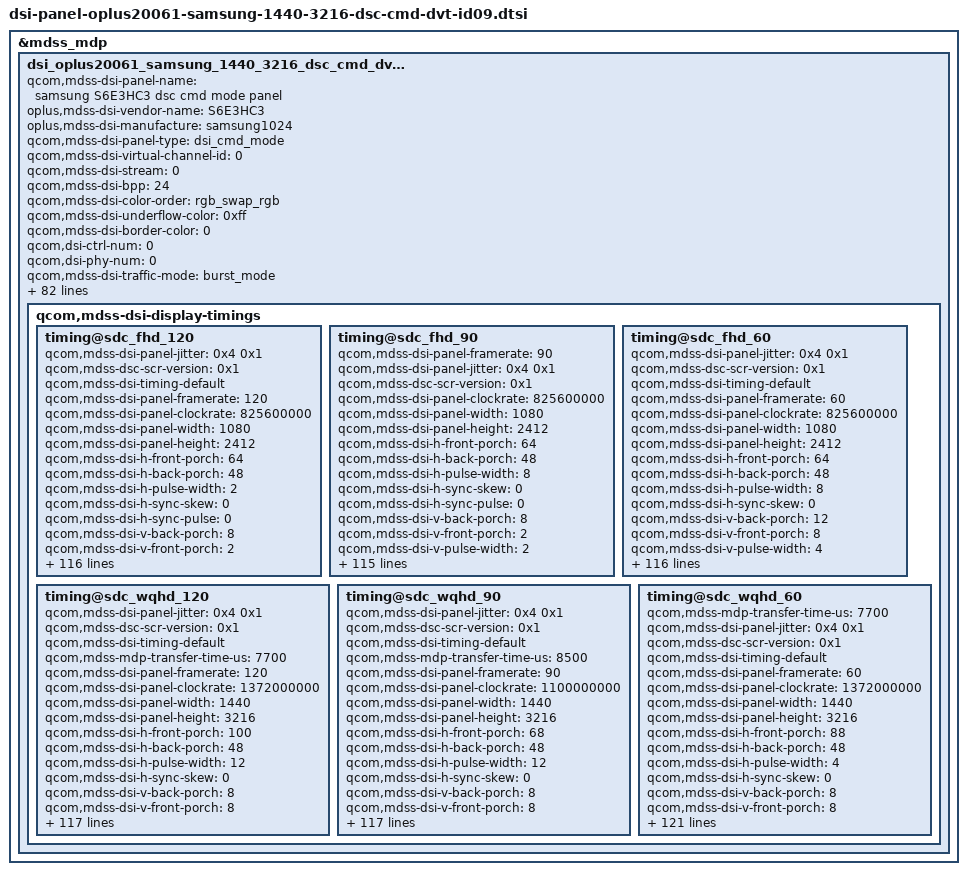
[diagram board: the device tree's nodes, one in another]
&mdss_mdp {
	dsi_oplus20061_samsung_1440_3216_dsc_cmd_dvt_id09: qcom,mdss_dsi_oplus20061_samsung_1440_3216_dsc_cmd_dvt_id09 {
		qcom,mdss-dsi-panel-name = "samsung S6E3HC3 dsc cmd mode panel";
		oplus,mdss-dsi-vendor-name = "S6E3HC3";
		oplus,mdss-dsi-manufacture = "samsung1024";
		qcom,mdss-dsi-panel-type = "dsi_cmd_mode";
		qcom,mdss-dsi-virtual-channel-id = <0>;
		qcom,mdss-dsi-stream = <0>;
		qcom,mdss-dsi-bpp = <24>;
		qcom,mdss-dsi-color-order = "rgb_swap_rgb";
		qcom,mdss-dsi-underflow-color = <0xff>;
		qcom,mdss-dsi-border-color = <0>;
		qcom,dsi-ctrl-num = <0>;
		qcom,dsi-phy-num = <0>;
		qcom,mdss-dsi-traffic-mode = "burst_mode";
		qcom,mdss-dsi-lane-map = "lane_map_0123";
		qcom,mdss-dsi-bllp-eof-power-mode;
		qcom,mdss-dsi-bllp-power-mode;
		qcom,mdss-dsi-lane-0-state;
		qcom,mdss-dsi-lane-1-state;
		qcom,mdss-dsi-lane-2-state;
		qcom,mdss-dsi-lane-3-state;
		qcom,mdss-dsi-dma-trigger = "trigger_sw";
		qcom,mdss-loading-effect;
		qcom,mdss-dsi-mdp-trigger = "none";
		qcom,mdss-dsi-reset-sequence = <1 10>, <0 5>, <1 10>;
		qcom,mdss-dsi-te-pin-select = <1>;
		qcom,mdss-dsi-te-dcs-command = <1>;
		qcom,mdss-pan-physical-width-dimension = <71>;
		qcom,mdss-pan-physical-height-dimension = <157>;
		qcom,mdss-dsi-init-delay-us = <1000>;
		qcom,mdss-dsi-te-check-enable;
		qcom,mdss-dsi-te-using-te-pin;
		qcom,mdss-dsi-lp11-init;
		qcom,mdss-dsi-wr-mem-start = <0x2c>;
		qcom,mdss-dsi-wr-mem-continue = <0x3c>;
		qcom,mdss-dsc-scr-version = <0x1>;
		/* HDR Setting */
		qcom,mdss-dsi-panel-hdr-enabled;
		qcom,mdss-dsi-panel-hdr-color-primaries = <15635 16450 34000 16000 13250 34500 7500 3000>;
		qcom,mdss-dsi-panel-peak-brightness = <5400000>;
		qcom,mdss-dsi-panel-average-brightness = <2000000>;
		qcom,mdss-dsi-panel-blackness-level = <4000>;

		qcom,esd-check-enabled;
		qcom,mdss-dsi-panel-status-check-mode = "reg_read";
		qcom,mdss-dsi-panel-status-command = [
				06 01 00 01 05 00 02 0A 00
			];
		qcom,mdss-dsi-panel-status-command-state = "dsi_hs_mode";
		qcom,mdss-dsi-panel-status-value = <0x9F>;
		qcom,mdss-dsi-panel-status-read-length = <1>;


		qcom,dynamic-mode-switch-enabled;
		qcom,dynamic-mode-switch-type = "dynamic-resolution-switch-immediate";
		qcom,mdss-dsi-display-timings {
			timing@sdc_fhd_120{
				qcom,mdss-dsi-panel-jitter = <0x4 0x1>;
				qcom,mdss-dsc-scr-version = <0x1>;
				qcom,mdss-dsi-timing-default;
				//qcom,mdss-mdp-transfer-time-us = <6000>;
				qcom,mdss-dsi-panel-framerate = <120>;
				qcom,mdss-dsi-panel-clockrate = <825600000>;
				qcom,mdss-dsi-panel-width = <1080>;
				qcom,mdss-dsi-panel-height = <2412>;

				qcom,mdss-dsi-h-front-porch = <64>;
				qcom,mdss-dsi-h-back-porch = <48>;
				qcom,mdss-dsi-h-pulse-width = <2>;
				qcom,mdss-dsi-h-sync-skew = <0>;
				qcom,mdss-dsi-h-sync-pulse = <0>;
				qcom,mdss-dsi-v-back-porch = <8>;
				qcom,mdss-dsi-v-front-porch = <2>;
				qcom,mdss-dsi-v-pulse-width = <2>;
				qcom,mdss-dsi-h-left-border = <0>;
				qcom,mdss-dsi-h-right-border = <0>;
				qcom,mdss-dsi-v-top-border = <0>;
				qcom,mdss-dsi-v-bottom-border = <0>;

				qcom,dsi-select-clocks = "mux_byte_clk0", "mux_pixel_clk0";

				oplus,fod-on-vblank = <0>;
				oplus,fod-off-vblank = <1>;
				qcom,mdss-dsi-panel-read-register-open-command = [
					39 01 00 00 00 00 03 F0 5A 5A
					];
				qcom,mdss-dsi-panel-id1-command = [
					06 01 00 00 00 00 01 E9
					];
				qcom,mdss-dsi-panel-read-register-close-command = [
					39 01 00 00 00 00 03 F0 A5 A5
					];
				qcom,mdss-dsi-timing-switch-command = [
					/* CASET/PASET Setting */
					39 00 00 00 00 00 05 2A 00 00 04 37
					39 00 00 00 00 00 05 2B 00 00 09 6B
					/* Scaler Setting */
					39 00 00 00 00 00 03 F0 5A 5A
					15 00 00 00 00 00 02 C3 89
					39 00 00 00 00 00 04 B0 00 24 C3
					39 00 00 00 00 00 12 C3 FD 00 FD 00 FD 00 FD 00 FD 00 FD 00 FD 00 FD 00 FD
					39 00 00 00 00 00 04 B0 00 3A C3
					39 00 00 00 00 00 12 C3 B0 00 B0 00 B0 00 B0 00 B0 00 B0 00 B0 00 B0 00 B0
					39 00 00 00 00 00 04 B0 00 50 C3
					39 00 00 00 00 00 12 C3 43 00 43 00 43 00 43 00 43 00 43 00 43 00 43 00 43
					39 00 00 00 00 00 04 B0 00 61 C3
					39 00 00 00 00 00 17 C3 CC CC CC CC C0 FE 00 FE 00 FE 00 FE 00 FE 00 FE 00 FE 00 FE 00 FE
					39 00 00 00 00 00 03 F0 A5 A5

					/* OPLUS ADFR OFF */
					39 00 00 00 00 00 03 F0 5A 5A
					39 00 00 00 00 00 03 FC 5A 5A
					15 00 00 00 00 00 02 B9 00						/* TP shift fixed */
					39 00 00 00 00 00 04 B0 00 02 60
					15 00 00 00 00 00 02 60 00						/* OPLUS ADFR OFF */
					39 00 00 00 00 00 03 F2 00 01					/* 0x01,0x00:ADFR ON setting 0x00,0x01:ADFR OFF Setting */
					15 00 00 00 00 00 02 F7 0F
					39 00 00 00 00 00 03 FC A5 A5
					39 00 00 00 00 00 03 F0 A5 A5

					/* TSP_HSYNC(SYNC1) Fixed Setting */
					39 00 00 00 00 00 03 F0 5A 5A
					39 00 00 00 00 00 04 B0 00 22 B9
					39 00 00 00 00 00 03 B9 A1 B1						/* TSP_SYNC1 = TSP_VSYNC ,  TSP_SYNC2 = TSP_HSYNC */
					39 00 00 00 00 00 04 B0 00 3A B9
					15 00 00 00 00 00 02 B9 02						/* TSP_VSYNC Fixed TE 02:120 03:90 05:60 */
					39 00 00 00 00 00 04 B0 00 26 B9
					39 00 00 00 00 00 03 B9 00 00
					15 00 00 00 00 00 02 F7 0F
					39 00 00 00 00 00 03 F0 A5 A5
					/* TSP_SYNC3 Fixed Setting */
					39 00 00 00 00 00 03 F0 5A 5A
					39 00 00 00 00 00 04 B0 00 24 B9
					15 00 00 00 00 00 02 B9 21
					39 00 00 00 00 00 04 B0 00 38 B9
					15 00 00 00 00 00 02 B9 02						/* TSP_VSYNC Fixed TE 02:120 03:90 05:60 */
					39 00 00 00 00 00 04 B0 00 2A B9
					39 00 00 00 00 00 03 B9 00 00
					15 00 00 00 00 00 02 F7 0F
					39 00 00 00 00 00 03 F0 A5 A5

					/* 120hz Transition */
					39 00 00 00 00 00 03 F0 5A 5A
					39 00 00 00 00 00 04 B0 00 16 F2
					39 00 00 00 00 00 03 F2 1B 50					/* 0x1B,0x50:120hz 0x24,0x70:90hz */
					39 00 00 00 00 00 03 BD 21 02					/* 0x21,0x02:120hz 0x21,0x03:90hz */
					15 00 00 00 00 00 02 60 00						/* 0x00:120hz 0x08:90hz 0x01:60hz */
					39 00 00 00 00 00 04 B0 00 10 BD
					15 00 00 00 00 00 02 BD 10						/* 0x00:1frame 0x10:2frame 0x20:3frame */
					15 00 00 00 00 00 02 F7 0F
					39 01 00 00 00 00 03 F0 A5 A5
				];
				qcom,mdss-dsi-on-command = [
					/* DSC Setting */
					39 01 00 00 00 00 5A 9E 11
					00 00 AB 30 80 09 6C 04 38
					00 24 02 1C 02 1C 02 00 02
					3B 00 20 03 35 00 07 00 0E
					03 34 02 D4 18 00 10 F0 07
					10 20 00 06 0F 0F 33 0E 1C
					2A 38 46 54 62 69 70 77 79
					7B 7D 7E 02 02 22 00 2A 40
					2A BE 3A FC 3A FA 3A F8 3B
					38 3B 78 3B B6 4B B6 4B F4
					4B F4 6C 34 84 74 00
					15 01 00 00 00 00 02 9D 01

					/* Sleep Out(11h) */
					05 01 00 00 05 00 01 11

					/* TSP_HSYNC(SYNC1) Fixed Setting */
					39 00 00 00 00 00 03 F0 5A 5A
					39 00 00 00 00 00 04 B0 00 22 B9
					39 00 00 00 00 00 03 B9 A1 B1						/* TSP_SYNC1 = TSP_VSYNC ,  TSP_SYNC2 = TSP_HSYNC */
					39 00 00 00 00 00 04 B0 00 3A B9
					15 00 00 00 00 00 02 B9 02						/* TSP_VSYNC Fixed TE 02:120 03:90 05:60 */
					39 00 00 00 00 00 04 B0 00 26 B9
					39 00 00 00 00 00 03 B9 00 00
					15 00 00 00 00 00 02 F7 0F
					39 01 00 00 00 00 03 F0 A5 A5
					/* TSP_SYNC3 Fixed Setting */
					39 00 00 00 00 00 03 F0 5A 5A
					39 00 00 00 00 00 04 B0 00 24 B9
					15 00 00 00 00 00 02 B9 21
					39 00 00 00 00 00 04 B0 00 38 B9
					15 00 00 00 00 00 02 B9 02						/* TSP_VSYNC Fixed TE 02:120 03:90 05:60 */
					39 00 00 00 00 00 04 B0 00 2A B9
					39 00 00 00 00 00 03 B9 00 00
					15 00 00 00 00 00 02 F7 0F
					39 01 00 00 78 00 03 F0 A5 A5
					/* 120hz Transition */
					39 00 00 00 00 00 03 F0 5A 5A
					39 00 00 00 00 00 04 B0 00 16 F2
					39 00 00 00 00 00 03 F2 1B 50					/* 0x1B,0x50:120hz 0x24,0x70:90hz */
					39 00 00 00 00 00 03 BD 21 02					/* 0x21,0x02:120hz 0x21,0x03:90hz */
					15 00 00 00 00 00 02 60 00						/* 0x00:120hz 0x08:90hz 0x01:60hz */
					39 00 00 00 00 00 04 B0 00 10 BD
					15 00 00 00 00 00 02 BD 10						/* 0x00:1frame 0x10:2frame 0x20:3frame */
					15 00 00 00 00 00 02 F7 0F
					39 01 00 00 00 00 03 F0 A5 A5
					
					/* Common Setting */
					39 00 00 00 00 00 03 F0 5A 5A
					39 00 00 00 00 00 03 F2 00 01					/* FQ_CON Setting */
					39 01 00 00 00 00 03 F0 A5 A5
					/* TE(Vsync) ON */
					39 00 00 00 00 00 03 F0 5A 5A
					15 00 00 00 00 00 02 35 00
					15 00 00 00 00 00 02 B9 00
					39 01 00 00 00 00 03 F0 A5 A5
					/* CASET/PASET Setting */
					39 00 00 00 00 00 05 2A 00 00 04 37
					39 01 00 00 00 00 05 2B 00 00 09 6B
					/* Loading effect compensation Control */
					39 00 00 00 00 00 03 F0 5A 5A
					39 00 00 00 00 00 04 B0 02 B6 1D
					15 00 00 00 00 00 02 1D 05
					39 01 00 00 00 00 03 F0 A5 A5
					/* Scaler Setting */
					39 00 00 00 00 00 03 F0 5A 5A
					15 00 00 00 00 00 02 C3 89
					39 00 00 00 00 00 04 B0 00 24 C3
					39 00 00 00 00 00 12 C3 FD 00 FD 00 FD 00 FD 00 FD 00 FD 00 FD 00 FD 00 FD
					39 00 00 00 00 00 04 B0 00 3A C3
					39 00 00 00 00 00 12 C3 B0 00 B0 00 B0 00 B0 00 B0 00 B0 00 B0 00 B0 00 B0
					39 00 00 00 00 00 04 B0 00 50 C3
					39 00 00 00 00 00 12 C3 43 00 43 00 43 00 43 00 43 00 43 00 43 00 43 00 43
					39 00 00 00 00 00 04 B0 00 61 C3
					39 00 00 00 00 00 17 C3 CC CC CC CC C0 FE 00 FE 00 FE 00 FE 00 FE 00 FE 00 FE 00 FE 00 FE
					39 01 00 00 00 00 03 F0 A5 A5

					/* Brightness Control */
					39 00 00 00 00 00 03 F0 5A 5A
					39 00 00 00 00 00 04 B0 00 0D 63
					15 00 00 00 00 00 02 63 01						/* Dimming Setting */
					39 00 00 00 00 00 04 B0 00 0C 63
					15 00 00 00 00 00 02 63 20
					39 00 00 00 00 00 03 F0 A5 A5
					15 00 00 00 00 00 02 53 20
					//15 01 00 00 00 00 02 F7 0F
					/* Pre-charge setting */
					39 01 00 00 00 00 03 F0 5A 5A
					39 01 00 00 00 00 04 B0 00 2b F6
					39 01 00 00 00 00 04 F6 60 63 69
					39 01 00 00 00 00 02 F7 0F
					39 01 00 00 00 00 03 F0 A5 A5
					/* OPEC ON */
					39 00 00 00 00 00 03 F0 5A 5A
					39 00 00 00 00 00 04 B0 00 56 1F
					39 00 00 00 00 00 11 1F 01 05 01 06 03 24 06 c0 06 c1 0d af 0d b0 1b b0
					39 00 00 00 00 00 04 B0 00 6A 1F
					39 00 00 00 00 00 1D 1F 01 05 03 24 04 4c 05 78 06 c0 08 34 09 c4 0b 54 0d af 0e 10 0e d8 0f a0 10 68 11 30
					39 00 00 00 00 00 04 B0 00 52 1F
					39 00 00 00 00 00 02 1F 02
					39 00 00 00 00 00 04 B0 00 54 1F
					39 00 00 00 00 00 02 1F 00
					39 01 00 00 00 00 03 F0 A5 A5

					/* ACL Mode */
					39 00 00 00 00 00 03 F0 5A 5A
					15 00 00 00 00 00 02 55 00
					39 01 00 00 00 00 03 F0 A5 A5

					/* Display On */
					//05 01 00 00 00 00 01 29
				];
				qcom,mdss-dsi-post-on-backlight = [
					/* Display On */
					05 01 00 00 00 00 01 29
				];
				qcom,mdss-dsi-off-command=[
					05 01 00 00 0A 00 02 28 00
					05 01 00 00 78 00 02 10 00
				];
				qcom,mdss-dsi-lp1-command = [
					05 01 00 00 11 00 01 28
					/* AOD Mode ON Setting */
					39 01 00 00 00 00 03 F0 5A 5A
					15 01 00 00 00 00 02 53 24
					//15 01 00 00 00 00 02 49 01
					39 01 00 00 24 00 03 F0 A5 A5
					05 01 00 00 00 00 01 29
				];
				qcom,mdss-dsi-nolp-command = [
					/* AOD OFF */
					39 01 00 00 00 00 03 F0 5A 5A
					15 01 00 00 00 00 02 53 28
					//15 01 00 00 00 00 02 49 02
					39 01 00 00 00 00 03 F0 A5 A5

					/* ELVSS DIM OFF  */
					39 01 00 00 00 00 03 F0 5A 5A
					39 01 00 00 00 00 04 B0 00 0C 63
					15 01 00 00 00 00 02 63 00
					39 01 00 00 00 00 03 F0 A5 A5
					/* HBM OFF Mode */
					39 01 00 00 00 00 02 53 20
					//39 01 00 00 00 00 03 51 07 FF
				];
				qcom,mdss-dsi-aod-hbm-on-command = [
					/* Loading OFF */
					39 00 00 00 00 00 03 f0 5a 5a
					39 00 00 00 00 00 04 b0 02 b6 1d
					39 00 00 00 00 00 02 1d 05
					39 00 00 00 00 00 03 f0 a5 a5
					/* aor 1.6% */
					39 00 00 00 00 00 03 f0 5a 5a
					39 00 00 00 00 00 04 b0 00 01 bd
					39 00 00 00 00 00 02 bd 02
					39 00 00 00 00 00 04 b0 02 b9 65
					39 00 00 00 00 00 07 65 00 ac 00 ac 00 ac
					39 00 00 00 00 00 02 f7 0f
					39 00 00 00 00 00 03 f0 a5 a5
					/* hbm on */
					15 00 00 00 00 00 02 53 e0
					39 01 00 00 09 00 03 51 0F 1F
				];
				qcom,mdss-dsi-aod-hbm-off-command = [
					/* HBM OFF Mode */
					39 01 00 00 00 00 02 53 20
					//39 01 00 00 00 00 03 51 07 FF
					/* AOD ON */
					39 01 00 00 00 00 03 F0 5A 5A
					15 01 00 00 00 00 02 53 24
					39 01 00 00 00 00 02 49 01
					39 01 00 00 09 00 03 F0 A5 A5
				];
				/*** pvt commond for ID1 >= 05 ***/
				qcom,mdss-dsi-lp1-pvt-command = [
					05 01 00 00 11 00 01 28
					/* AOD Mode ON Setting */
					39 01 00 00 00 00 03 F0 5A 5A
					15 01 00 00 00 00 02 53 24
					39 01 00 00 24 00 03 F0 A5 A5
					05 01 00 00 00 00 01 29
				];
				qcom,mdss-dsi-nolp-pvt-command = [
					/* AOD OFF */
					39 01 00 00 00 00 03 F0 5A 5A
					15 01 00 00 00 00 02 53 28
					39 01 00 00 00 00 03 F0 A5 A5
					/* HBM OFF Mode */
					39 01 00 00 00 00 02 53 20
					//39 01 00 00 00 00 03 51 07 FF
				];
				qcom,mdss-dsi-aod-hbm-on-pvt-command = [
					/* Loading OFF */
					39 00 00 00 00 00 03 f0 5a 5a
					39 00 00 00 00 00 04 b0 02 b6 1d
					39 00 00 00 00 00 02 1d 05
					39 00 00 00 00 00 03 f0 a5 a5
					/* aor 1.6% */
					39 00 00 00 00 00 03 f0 5a 5a
					39 00 00 00 00 00 04 b0 00 01 bd
					39 00 00 00 00 00 02 bd 02
					39 00 00 00 00 00 04 b0 02 b9 65
					39 00 00 00 00 00 07 65 00 ac 00 ac 00 ac
					39 00 00 00 00 00 02 f7 0f
					39 00 00 00 00 00 03 f0 a5 a5
					/* hbm on */
					15 00 00 00 00 00 02 53 e0
					39 01 00 00 09 00 03 51 0F 1F
				];
				qcom,mdss-dsi-aod-hbm-off-pvt-command = [
					/* HBM OFF Mode */
					39 01 00 00 00 00 02 53 20
					//39 01 00 00 00 00 03 51 07 FF
					/* AOD ON */
					39 01 00 00 00 00 03 F0 5A 5A
					15 01 00 00 00 00 02 53 24
					39 01 00 00 09 00 03 F0 A5 A5
				];
				qcom,mdss-dsi-hbm-off-command = [
					/* HBM OFF Mode */
					39 00 00 00 00 00 03 f0 5a 5a
					39 00 00 00 00 00 04 b0 00 0c 63
					15 00 00 00 00 00 02 63 20
					39 00 00 00 00 00 03 f0 a5 a5
					39 01 00 00 09 00 02 53 28
				];
				qcom,mdss-dsi-hbm-on-command = [
					/* DLY ON */
					39 00 00 00 00 00 03 f0 5a 5a
					39 00 00 00 00 00 04 b0 00 0c 63
					39 00 00 00 00 00 02 63 20
					39 01 00 00 09 00 03 f0 a5 a5
					/* Loading OFF */
					39 00 00 00 00 00 03 f0 5a 5a
					39 00 00 00 00 00 04 b0 02 b6 1d
					39 00 00 00 00 00 02 1d 05
					39 00 00 00 00 00 03 f0 a5 a5
					/* aor 1.6% */
					39 00 00 00 00 00 03 f0 5a 5a
					39 00 00 00 00 00 04 b0 00 01 bd
					39 00 00 00 00 00 02 bd 02
					39 00 00 00 00 00 04 b0 02 b9 65
					39 00 00 00 00 00 07 65 00 ac 00 ac 00 ac
					39 00 00 00 00 00 02 f7 0f
					39 00 00 00 00 00 03 f0 a5 a5
					/* hbm on */
					15 01 00 00 09 00 02 53 e0
					39 01 00 00 00 00 03 51 0F 1F
				];
				qcom,mdss-dsi-normal-hbm-on-command = [
					/* Loading OFF */
					39 00 00 00 00 00 03 f0 5a 5a
					39 00 00 00 00 00 04 b0 02 b6 1d
					39 00 00 00 00 00 02 1d 05
					39 00 00 00 00 00 03 f0 a5 a5
					/* aor 1.6% */
					39 00 00 00 00 00 03 f0 5a 5a
					39 00 00 00 00 00 04 b0 00 01 bd
					39 00 00 00 00 00 02 bd 02
					39 00 00 00 00 00 04 b0 02 b9 65
					39 00 00 00 00 00 07 65 00 ac 00 ac 00 ac
					39 00 00 00 00 00 02 f7 0f
					39 00 00 00 00 00 03 f0 a5 a5
					/* hbm on */
					15 01 00 00 09 00 02 53 e0
					39 01 00 00 00 00 03 51 0F 1F
				];
				qcom,mdss-dsi-hbm-enter-switch-command = [
					15 01 00 00 00 00 02 53 E0
				];
				qcom,mdss-dsi-hbm-exit-switch-command = [
					39 01 00 00 00 00 02 53 20
					//39 01 00 00 00 00 03 51 07 FF
				];
				qcom,mdss-dsi-aor-restore-command = [
					/* AOR 16% */
					39 00 00 00 00 00 03 f0 5a 5a
					39 00 00 00 00 00 04 b0 00 01 bd
					39 00 00 00 00 00 02 bd 02
					39 00 00 00 00 00 04 b0 02 b9 65
					39 00 00 00 00 00 07 65 01 5e 01 5e 01 5e
					39 00 00 00 00 00 02 f7 0f
					39 01 00 00 00 00 03 f0 a5 a5
				];
				qcom,mdss-dsi-aod-high-mode-command = [
					/* AOD 50nit */
					39 01 00 00 00 00 03 F0 5A 5A
					15 01 00 00 00 00 02 53 24
					//39 01 00 00 00 00 02 6A 00
					39 01 00 00 00 00 03 F0 A5 A5
				];
				qcom,mdss-dsi-aod-low-mode-command = [
					/* AOD 10nit */
					39 01 00 00 00 00 03 F0 5A 5A
					15 01 00 00 00 00 02 53 27
					//39 01 00 00 00 00 02 6A 00
					39 01 00 00 00 00 03 F0 A5 A5
				];
				qcom,mdss-dsi-seed-off-command = [
					/* SEED CRC OFF*/
					15 01 00 00 00 00 02 1C 00
					/* SEED CRC BYPASS */
					39 01 00 00 00 00 03 F0 5A 5A
					15 01 00 00 00 00 02 1D 01
					39 01 00 00 00 00 03 F0 A5 A5
				];
				qcom,mdss-dsi-seed-0-command = [
					/* SEED CRC Setting*/
					15 01 00 00 00 00 02 1C 05
					39 01 00 00 00 00 03 F0 5A 5A
					39 01 00 00 00 00 04 B0 00 01 1D
					/* SEED DCI-P3 Setting*/
					39 01 00 00 00 00 16 1D FF 00 00 00 FF 00 00 00 FF 00 FF FF FF 00 FF FF FF 00 FF FF FF
					15 01 00 00 00 00 02 1D 00
					39 01 00 00 00 00 03 F0 A5 A5
				];
				qcom,mdss-dsi-seed-1-command = [
					/* SEED CRC Setting*/
					15 01 00 00 00 00 02 1C 05
					39 01 00 00 00 00 03 F0 5A 5A
					39 01 00 00 00 00 04 B0 00 01 1D
					/* SEED DCI-P3 Setting*/
					39 01 00 00 00 00 16 1D FF 00 00 00 FF 00 00 00 FF 00 FF FF FF 00 FF FF FF 00 FF FF FF
					15 01 00 00 00 00 02 1D 00
					39 01 00 00 00 00 03 F0 A5 A5
				];
				qcom,mdss-dsi-seed-2-command = [
					/* SEED CRC Setting*/
					15 01 00 00 00 00 02 1C 05
					39 01 00 00 00 00 03 F0 5A 5A
					39 01 00 00 00 00 04 B0 00 01 1D
					/* SEED DCI-P3 Setting*/
					39 01 00 00 00 00 16 1D FF 00 00 00 FF 00 00 00 FF 00 FF FF FF 00 FF FF FF 00 FF FF FF
					15 01 00 00 00 00 02 1D 00
					39 01 00 00 00 00 03 F0 A5 A5
				];
				qcom,mdss-dsi-loading-effect-1-command = [
					39 00 00 00 00 00 03 F0 5A 5A
					39 00 00 00 00 00 04 B0 02 B6 1D
					39 00 00 00 00 00 02 1D 25
					39 00 00 00 00 00 04 B0 01 A5 1F
					39 00 00 00 00 00 09 1F E2 00 00 00 92 2C 6A 80
					39 00 00 00 00 00 04 B0 01 AD 1F
					39 00 00 00 00 00 07 1F 00 00 00 00 FF 90
					39 00 00 00 00 00 04 B0 01 B5 1F
					39 00 00 00 00 00 04 1F 49 00 10
					39 00 00 00 00 00 04 B0 01 BA 1F
					39 00 00 00 00 00 06 1F 05 FF 10 00 00
					39 00 00 00 00 00 04 B0 01 C1 1F
					39 00 00 00 00 00 05 1F 00 00 00 00
					39 00 00 00 00 00 04 B0 01 C5 1F
					39 00 00 00 00 00 05 1F 03 FF 21 3C
					39 01 00 00 00 00 03 F0 A5 A5
				];
				qcom,mdss-dsi-loading-effect-2-command = [
					39 00 00 00 00 00 03 F0 5A 5A
					39 00 00 00 00 00 04 B0 02 B6 1D
					39 00 00 00 00 00 02 1D 25
					39 00 00 00 00 00 04 B0 01 A5 1F
					39 00 00 00 00 00 09 1F E2 00 00 00 92 2C 6A 80
					39 00 00 00 00 00 04 B0 01 AD 1F
					39 00 00 00 00 00 07 1F 7D 64 7E 65 FF 90
					39 00 00 00 00 00 04 B0 01 B5 1F
					39 00 00 00 00 00 04 1F 49 00 10
					39 00 00 00 00 00 04 B0 01 BA 1F
					39 00 00 00 00 00 06 1F 05 FF 10 00 00
					39 00 00 00 00 00 04 B0 01 C1 1F
					39 00 00 00 00 00 05 1F 00 00 00 00
					39 00 00 00 00 00 04 B0 01 C5 1F
					39 00 00 00 00 00 05 1F 03 FF 21 3C
					39 01 00 00 00 00 03 F0 A5 A5
				];
				qcom,mdss-dsi-loading-effect-off-command = [
					39 00 00 00 00 00 03 F0 5A 5A
					39 00 00 00 00 00 04 B0 02 B6 1D
					39 00 00 00 00 00 02 1D 05
					39 01 00 00 00 00 03 F0 A5 A5
				];
				qcom,mdss-dsi-aod-hbm-on-command-state = "dsi_hs_mode";
				qcom,mdss-dsi-aod-hbm-off-command-state = "dsi_hs_mode";
				qcom,mdss-dsi-timing-switch-command-state = "dsi_hs_mode";
				qcom,mdss-dsi-on-command-state = "dsi_lp_mode";
				qcom,mdss-dsi-off-command-state = "dsi_hs_mode";
				qcom,mdss-dsi-seed-off-command-state = "dsi_hs_mode";
				qcom,mdss-dsi-seed-0-command-state = "dsi_hs_mode";
				qcom,mdss-dsi-seed-1-command-state = "dsi_hs_mode";
				qcom,mdss-dsi-seed-2-command-state = "dsi_hs_mode";
				qcom,mdss-dsi-loading-effect-1-command-state = "dsi_hs_mode";
				qcom,mdss-dsi-loading-effect-2-command-state = "dsi_hs_mode";
				qcom,mdss-dsi-loading-effect-off-command-state = "dsi_hs_mode";
				qcom,mdss-dsi-hbm-on-command-state = "dsi_hs_mode";
				qcom,mdss-dsi-hbm-off-command-state = "dsi_hs_mode";
				qcom,mdss-dsi-aor-restore-command-state = "dsi_hs_mode";

				qcom,compression-mode = "dsc";
				qcom,lm-split = <540 540>;
				qcom,mdss-dsc-encoders = <2>;
				qcom,mdss-dsc-slice-height = <36>;
				qcom,mdss-dsc-slice-width = <540>;
				qcom,mdss-dsc-slice-per-pkt = <2>;
				qcom,mdss-dsc-bit-per-component = <10>;
				qcom,mdss-dsc-bit-per-pixel = <8>;
				qcom,mdss-dsc-block-prediction-enable;
				qcom,mdss-dsi-panel-id1-command-state = "dsi_lp_mode";
				qcom,mdss-dsi-panel-read-register-open-state = "dsi_lp_mode";
				qcom,mdss-dsi-panel-read-register-close-state = "dsi_lp_mode";
			};
			timing@sdc_fhd_90{
				//qcom,mdss-dsi-timing-default;
				//qcom,mdss-mdp-transfer-time-us = <7700>;
				qcom,mdss-dsi-panel-framerate = <90>;
				qcom,mdss-dsi-panel-jitter = <0x4 0x1>;
				qcom,mdss-dsc-scr-version = <0x1>;
				qcom,mdss-dsi-panel-clockrate = <825600000>;
				qcom,mdss-dsi-panel-width = <1080>;
				qcom,mdss-dsi-panel-height = <2412>;

				qcom,mdss-dsi-h-front-porch = <64>;
				qcom,mdss-dsi-h-back-porch = <48>;
				qcom,mdss-dsi-h-pulse-width = <8>;
				qcom,mdss-dsi-h-sync-skew = <0>;
				qcom,mdss-dsi-h-sync-pulse = <0>;
				qcom,mdss-dsi-v-back-porch = <8>;
				qcom,mdss-dsi-v-front-porch = <2>;
				qcom,mdss-dsi-v-pulse-width = <2>;
				qcom,mdss-dsi-h-left-border = <0>;
				qcom,mdss-dsi-h-right-border = <0>;
				qcom,mdss-dsi-v-top-border = <0>;
				qcom,mdss-dsi-v-bottom-border = <0>;

				qcom,dsi-select-clocks = "mux_byte_clk0", "mux_pixel_clk0";

				oplus,fod-on-vblank = <0>;
				oplus,fod-off-vblank = <1>;
				qcom,mdss-dsi-panel-read-register-open-command = [
					39 01 00 00 00 00 03 F0 5A 5A
					];
				qcom,mdss-dsi-panel-id1-command = [
					06 01 00 00 00 00 01 E9
					];
				qcom,mdss-dsi-panel-read-register-close-command = [
					39 01 00 00 00 00 03 F0 A5 A5
					];
				qcom,mdss-dsi-timing-switch-command = [
					/* CASET/PASET Setting */
					39 00 00 00 00 00 05 2A 00 00 04 37
					39 00 00 00 00 00 05 2B 00 00 09 6B
					/* Scaler Setting */
					39 00 00 00 00 00 03 F0 5A 5A
					15 00 00 00 00 00 02 C3 89
					39 00 00 00 00 00 04 B0 00 24 C3
					39 00 00 00 00 00 12 C3 FD 00 FD 00 FD 00 FD 00 FD 00 FD 00 FD 00 FD 00 FD
					39 00 00 00 00 00 04 B0 00 3A C3
					39 00 00 00 00 00 12 C3 B0 00 B0 00 B0 00 B0 00 B0 00 B0 00 B0 00 B0 00 B0
					39 00 00 00 00 00 04 B0 00 50 C3
					39 00 00 00 00 00 12 C3 43 00 43 00 43 00 43 00 43 00 43 00 43 00 43 00 43
					39 00 00 00 00 00 04 B0 00 61 C3
					39 00 00 00 00 00 17 C3 CC CC CC CC C0 FE 00 FE 00 FE 00 FE 00 FE 00 FE 00 FE 00 FE 00 FE
					39 00 00 00 00 00 03 F0 A5 A5

					/* OPLUS ADFR OFF */
					39 00 00 00 00 00 03 F0 5A 5A
					39 00 00 00 00 00 03 FC 5A 5A
					15 00 00 00 00 00 02 B9 00						/* TP shift fixed */
					39 00 00 00 00 00 04 B0 00 02 60
					15 00 00 00 00 00 02 60 00						/* OPLUS ADFR OFF */
					39 00 00 00 00 00 03 F2 00 01					/* 0x01,0x00:ADFR ON setting 0x00,0x01:ADFR OFF Setting */
					15 00 00 00 00 00 02 F7 0F
					39 00 00 00 00 00 03 FC A5 A5
					39 00 00 00 00 00 03 F0 A5 A5

					/* TSP_HSYNC(SYNC1) Fixed Setting */
					39 00 00 00 00 00 03 F0 5A 5A
					39 00 00 00 00 00 04 B0 00 22 B9
					39 00 00 00 00 00 03 B9 A1 B1						/* TSP_SYNC1 = TSP_VSYNC ,  TSP_SYNC2 = TSP_HSYNC */
					39 00 00 00 00 00 04 B0 00 3A B9
					15 00 00 00 00 00 02 B9 03						/* TSP_VSYNC Fixed TE 02:120 03:90 05:60 */
					39 00 00 00 00 00 04 B0 00 26 B9
					39 00 00 00 00 00 03 B9 00 00
					15 00 00 00 00 00 02 F7 0F
					39 00 00 00 00 00 03 F0 A5 A5
					/* TSP_SYNC3 Fixed Setting */
					39 00 00 00 00 00 03 F0 5A 5A
					39 00 00 00 00 00 04 B0 00 24 B9
					15 00 00 00 00 00 02 B9 21
					39 00 00 00 00 00 04 B0 00 38 B9
					15 00 00 00 00 00 02 B9 03						/* TSP_VSYNC Fixed TE 02:120 03:90 05:60 */
					39 00 00 00 00 00 04 B0 00 2A B9
					39 00 00 00 00 00 03 B9 00 00
					15 00 00 00 00 00 02 F7 0F
					39 00 00 00 00 00 03 F0 A5 A5

					/* 90hz Transition */
					39 00 00 00 00 00 03 F0 5A 5A
					39 00 00 00 00 00 04 B0 00 16 F2
					39 00 00 00 00 00 03 F2 24 70					/* 0x1B,0x50:120hz 0x24,0x70:90hz */
					39 00 00 00 00 00 03 BD 21 03					/* 0x21,0x02:120hz 0x21,0x03:90hz */
					15 00 00 00 00 00 02 60 08						/* 0x00:120hz 0x08:90hz 0x01:60hz */
					39 00 00 00 00 00 04 B0 00 10 BD
					15 00 00 00 00 00 02 BD 10						/* 0x00:1frame 0x10:2frame 0x20:3frame */
					15 00 00 00 00 00 02 F7 0F
					39 01 00 00 00 00 03 F0 A5 A5
				];
				qcom,mdss-dsi-on-command = [
					/* DSC Setting */
					39 01 00 00 00 00 5A 9E 11
					00 00 AB 30 80 09 6C 04 38
					00 24 02 1C 02 1C 02 00 02
					3B 00 20 03 35 00 07 00 0E
					03 34 02 D4 18 00 10 F0 07
					10 20 00 06 0F 0F 33 0E 1C
					2A 38 46 54 62 69 70 77 79
					7B 7D 7E 02 02 22 00 2A 40
					2A BE 3A FC 3A FA 3A F8 3B
					38 3B 78 3B B6 4B B6 4B F4
					4B F4 6C 34 84 74 00
					15 01 00 00 00 00 02 9D 01

					/* Sleep Out(11h) */
					05 01 00 00 05 00 01 11

					/* TSP_HSYNC(SYNC1) Fixed Setting */
					39 00 00 00 00 00 03 F0 5A 5A
					39 00 00 00 00 00 04 B0 00 22 B9
					39 00 00 00 00 00 03 B9 A1 B1						/* TSP_SYNC1 = TSP_VSYNC ,  TSP_SYNC2 = TSP_HSYNC */
					39 00 00 00 00 00 04 B0 00 3A B9
					15 00 00 00 00 00 02 B9 03						/* TSP_VSYNC Fixed TE 02:120 03:90 05:60 */
					39 00 00 00 00 00 04 B0 00 26 B9
					39 00 00 00 00 00 03 B9 00 00
					15 00 00 00 00 00 02 F7 0F
					39 00 00 00 00 00 03 F0 A5 A5
					/* TSP_SYNC3 Fixed Setting */
					39 00 00 00 00 00 03 F0 5A 5A
					39 00 00 00 00 00 04 B0 00 24 B9
					15 00 00 00 00 00 02 B9 21
					39 00 00 00 00 00 04 B0 00 38 B9
					15 00 00 00 00 00 02 B9 03						/* TSP_VSYNC Fixed TE 02:120 03:90 05:60 */
					39 00 00 00 00 00 04 B0 00 2A B9
					39 00 00 00 00 00 03 B9 00 00
					15 00 00 00 00 00 02 F7 0F
					39 01 00 00 78 00 03 F0 A5 A5
					/* 90hz Transition */
					39 00 00 00 00 00 03 F0 5A 5A
					39 00 00 00 00 00 04 B0 00 16 F2
					39 00 00 00 00 00 03 F2 24 70					/* 0x1B,0x50:120hz 0x24,0x70:90hz */
					39 00 00 00 00 00 03 BD 21 03					/* 0x21,0x02:120hz 0x21,0x03:90hz */
					15 00 00 00 00 00 02 60 08						/* 0x00:120hz 0x08:90hz 0x01:60hz */
					39 00 00 00 00 00 04 B0 00 10 BD
					15 00 00 00 00 00 02 BD 10						/* 0x00:1frame 0x10:2frame 0x20:3frame */
					15 00 00 00 00 00 02 F7 0F
					39 01 00 00 00 00 03 F0 A5 A5
					
					/* Common Setting */
					39 00 00 00 00 00 03 F0 5A 5A
					39 00 00 00 00 00 03 F2 00 01					/* FQ_CON Setting */
					39 01 00 00 00 00 03 F0 A5 A5
					/* TE(Vsync) ON */
					39 00 00 00 00 00 03 F0 5A 5A
					15 00 00 00 00 00 02 35 00
					15 00 00 00 00 00 02 B9 00
					39 01 00 00 00 00 03 F0 A5 A5
					/* CASET/PASET Setting */
					39 00 00 00 00 00 05 2A 00 00 04 37
					39 01 00 00 00 00 05 2B 00 00 09 6B
					/* Loading effect compensation Control */
					39 00 00 00 00 00 03 F0 5A 5A
					39 00 00 00 00 00 04 B0 02 B6 1D
					15 00 00 00 00 00 02 1D 05
					39 01 00 00 00 00 03 F0 A5 A5
					/* Scaler Setting */
					39 00 00 00 00 00 03 F0 5A 5A
					15 00 00 00 00 00 02 C3 89
					39 00 00 00 00 00 04 B0 00 24 C3
					39 00 00 00 00 00 12 C3 FD 00 FD 00 FD 00 FD 00 FD 00 FD 00 FD 00 FD 00 FD
					39 00 00 00 00 00 04 B0 00 3A C3
					39 00 00 00 00 00 12 C3 B0 00 B0 00 B0 00 B0 00 B0 00 B0 00 B0 00 B0 00 B0
					39 00 00 00 00 00 04 B0 00 50 C3
					39 00 00 00 00 00 12 C3 43 00 43 00 43 00 43 00 43 00 43 00 43 00 43 00 43
					39 00 00 00 00 00 04 B0 00 61 C3
					39 00 00 00 00 00 17 C3 CC CC CC CC C0 FE 00 FE 00 FE 00 FE 00 FE 00 FE 00 FE 00 FE 00 FE
					39 01 00 00 00 00 03 F0 A5 A5

					/* Brightness Control */
					39 00 00 00 00 00 03 F0 5A 5A
					39 00 00 00 00 00 04 B0 00 0D 63
					15 00 00 00 00 00 02 63 01						/* Dimming Setting */
					39 00 00 00 00 00 04 B0 00 0C 63
					15 00 00 00 00 00 02 63 20
					39 01 00 00 00 00 03 F0 A5 A5
					15 01 00 00 00 00 02 53 20
					//15 01 00 00 00 00 02 F7 0F
					/* Pre-charge setting */
					39 01 00 00 00 00 03 F0 5A 5A
					39 01 00 00 00 00 04 B0 00 2b F6
					39 01 00 00 00 00 04 F6 60 63 69
					39 01 00 00 00 00 02 F7 0F
					39 01 00 00 00 00 03 F0 A5 A5
					/* OPEC ON */
					39 00 00 00 00 00 03 F0 5A 5A
					39 00 00 00 00 00 04 B0 00 56 1F
					39 00 00 00 00 00 11 1F 01 05 01 06 03 24 06 c0 06 c1 0d af 0d b0 1b b0
					39 00 00 00 00 00 04 B0 00 6A 1F
					39 00 00 00 00 00 1D 1F 01 05 03 24 04 4c 05 78 06 c0 08 34 09 c4 0b 54 0d af 0e 10 0e d8 0f a0 10 68 11 30
					39 00 00 00 00 00 04 B0 00 52 1F
					39 00 00 00 00 00 02 1F 02
					39 00 00 00 00 00 04 B0 00 54 1F
					39 00 00 00 00 00 02 1F 00
					39 01 00 00 00 00 03 F0 A5 A5

					/* ACL Mode */
					39 00 00 00 00 00 03 F0 5A 5A
					15 00 00 00 00 00 02 55 00
					39 01 00 00 00 00 03 F0 A5 A5

					/* Display On */
					//05 01 00 00 00 00 01 29
				];
				qcom,mdss-dsi-post-on-backlight = [
					/* Display On */
					05 01 00 00 00 00 01 29
				];
				qcom,mdss-dsi-off-command=[
					05 01 00 00 0A 00 02 28 00
					05 01 00 00 78 00 02 10 00
				];
				qcom,mdss-dsi-lp1-command = [
					05 01 00 00 11 00 01 28
					/* AOD Mode ON Setting */
					39 01 00 00 00 00 03 F0 5A 5A
					15 01 00 00 00 00 02 53 24
					//15 01 00 00 00 00 02 49 01
					39 01 00 00 24 00 03 F0 A5 A5
					05 01 00 00 00 00 01 29
				];
				qcom,mdss-dsi-nolp-command = [
					/* AOD OFF */
					39 00 00 00 00 00 03 F0 5A 5A
					15 00 00 00 00 00 02 53 28
					39 01 00 00 00 00 03 F0 A5 A5

					/* AOR 16% */
					39 00 00 00 00 00 03 f0 5a 5a
					39 00 00 00 00 00 04 b0 00 01 bd
					39 00 00 00 00 00 02 bd 02
					39 00 00 00 00 00 04 b0 02 d9 65
					39 00 00 00 00 00 07 65 01 06 01 06 01 06
					39 00 00 00 00 00 02 f7 0f
					39 01 00 00 00 00 03 f0 a5 a5
					/* HBM OFF Mode */
					39 01 00 00 00 00 02 53 20
					//39 01 00 00 00 00 03 51 07 FF
				];
				qcom,mdss-dsi-aod-hbm-on-command = [
					/* Loading OFF */
					39 00 00 00 00 00 03 F0 5A 5A
					39 00 00 00 00 00 04 B0 02 B6 1D
					39 00 00 00 00 00 02 1D 05
					39 01 00 00 00 00 03 F0 A5 A5
					/* AOD OFF */
					39 00 00 00 00 00 03 F0 5A 5A
					39 00 00 00 00 00 02 53 28
					39 01 00 00 00 00 03 F0 A5 A5
					/* AOR 1.6% */
					39 00 00 00 00 00 03 F0 5A 5A
					39 00 00 00 00 00 04 B0 00 01 BD
					39 00 00 00 00 00 02 BD 00
					39 00 00 00 00 00 04 B0 02 d9 65
					39 00 00 00 00 00 07 65 00 AC 00 AC 00 AC
					39 00 00 00 00 00 02 F7 0F
					39 01 00 00 00 00 03 F0 A5 A5
					/* Hbm ON */
					15 01 00 00 00 00 02 53 E0
					39 01 00 00 00 00 03 51 0F 1F
				];
				qcom,mdss-dsi-aod-hbm-off-command = [
					/* HBM OFF Mode */
					39 01 00 00 00 00 02 53 20
					//39 01 00 00 00 00 03 51 07 FF
					/* AOD ON */
					39 01 00 00 00 00 03 F0 5A 5A
					15 01 00 00 00 00 02 53 24
					39 01 00 00 00 00 02 49 01
					39 01 00 00 00 00 03 F0 A5 A5
				];
				/*** pvt commond for ID1 >= 05 ***/
				qcom,mdss-dsi-lp1-pvt-command = [
					05 01 00 00 11 00 01 28
					/* AOD Mode ON Setting */
					39 01 00 00 00 00 03 F0 5A 5A
					15 01 00 00 00 00 02 53 24
					39 01 00 00 24 00 03 F0 A5 A5
					05 01 00 00 00 00 01 29
				];
				qcom,mdss-dsi-nolp-pvt-command = [
					/* AOD OFF */
					39 01 00 00 00 00 03 F0 5A 5A
					15 01 00 00 00 00 02 53 28
					39 01 00 00 00 00 03 F0 A5 A5
					/* HBM OFF Mode */
					39 01 00 00 00 00 02 53 20
					//39 01 00 00 00 00 03 51 07 FF
				];
				qcom,mdss-dsi-aod-hbm-on-pvt-command = [
					/* Loading OFF */
					39 00 00 00 00 00 03 F0 5A 5A
					39 00 00 00 00 00 04 B0 02 B6 1D
					39 00 00 00 00 00 02 1D 05
					39 01 00 00 00 00 03 F0 A5 A5
					/* AOD OFF */
					39 00 00 00 00 00 03 F0 5A 5A
					39 00 00 00 00 00 02 53 28
					39 01 00 00 00 00 03 F0 A5 A5
					/* AOR 1.6% */
					39 00 00 00 00 00 03 F0 5A 5A
					39 00 00 00 00 00 04 B0 00 01 BD
					39 00 00 00 00 00 02 BD 00
					39 00 00 00 00 00 04 B0 02 D9 65
					39 00 00 00 00 00 07 65 00 AC 00 AC 00 AC
					39 00 00 00 00 00 02 F7 0F
					39 01 00 00 00 00 03 F0 A5 A5
					/* Hbm ON */
					15 01 00 00 00 00 02 53 E0
					39 01 00 00 00 00 03 51 0F 1F
				];
				qcom,mdss-dsi-aod-hbm-off-pvt-command = [
					/* HBM OFF Mode */
					39 01 00 00 00 00 02 53 20
					//39 01 00 00 00 00 03 51 07 FF
					/* AOD ON */
					39 01 00 00 00 00 03 F0 5A 5A
					15 01 00 00 00 00 02 53 24
					39 01 00 00 00 00 03 F0 A5 A5
				];
				qcom,mdss-dsi-hbm-off-command = [
					/* HBM OFF Mode */
					39 01 00 00 00 00 02 53 28
					//39 01 00 00 00 00 03 51 07 FF
				];
				qcom,mdss-dsi-hbm-on-command = [
					/* DLY ON */
					39 00 00 00 00 00 03 f0 5a 5a
					39 00 00 00 00 00 04 b0 00 0c 63
					39 00 00 00 00 00 02 63 20
					39 01 00 00 09 00 03 f0 a5 a5
					/* Loading OFF */
					39 00 00 00 00 00 03 F0 5A 5A
					39 00 00 00 00 00 04 B0 02 B6 1D
					39 00 00 00 00 00 02 1D 05
					39 01 00 00 00 00 03 F0 A5 A5
					/* AOR 1.6% */
					39 00 00 00 00 00 03 F0 5A 5A
					39 00 00 00 00 00 04 B0 00 01 BD
					39 00 00 00 00 00 02 BD 00
					39 00 00 00 00 00 04 B0 02 d9 65
					39 00 00 00 00 00 07 65 00 AC 00 AC 00 AC
					39 00 00 00 00 00 02 F7 0F
					39 01 00 00 00 00 03 F0 A5 A5
					/* Hbm ON */
					15 01 00 00 00 00 02 53 E0
					39 01 00 00 00 00 03 51 0F 1F
				];
				qcom,mdss-dsi-normal-hbm-on-command = [
					/* Loading OFF */
					39 00 00 00 00 00 03 F0 5A 5A
					39 00 00 00 00 00 04 B0 02 B6 1D
					39 00 00 00 00 00 02 1D 05
					39 01 00 00 00 00 03 F0 A5 A5
					/* AOR 1.6% */
					39 00 00 00 00 00 03 F0 5A 5A
					39 00 00 00 00 00 04 B0 00 01 BD
					39 00 00 00 00 00 02 BD 00
					39 00 00 00 00 00 04 B0 02 d9 65
					39 00 00 00 00 00 07 65 00 AC 00 AC 00 AC
					39 00 00 00 00 00 02 F7 0F
					39 01 00 00 00 00 03 F0 A5 A5
					/* Hbm ON */
					15 01 00 00 00 00 02 53 E0
					39 01 00 00 00 00 03 51 0F 1F
				];
				qcom,mdss-dsi-hbm-enter-switch-command = [
					15 01 00 00 00 00 02 53 E0
				];
				qcom,mdss-dsi-hbm-exit-switch-command = [
					39 01 00 00 00 00 02 53 20
					//39 01 00 00 00 00 03 51 07 FF
				];
				qcom,mdss-dsi-aor-restore-command = [
					/* AOR 16% */
					39 00 00 00 00 00 03 f0 5a 5a
					39 00 00 00 00 00 04 b0 00 01 bd
					39 00 00 00 00 00 02 bd 03
					39 00 00 00 00 00 04 b0 02 d9 65
					39 00 00 00 00 00 07 65 01 06 01 06 01 06
					39 00 00 00 00 00 02 f7 0f
					39 01 00 00 00 00 03 f0 a5 a5
				];
				qcom,mdss-dsi-aod-high-mode-command = [
					/* AOD 50nit */
					39 01 00 00 00 00 03 F0 5A 5A
					15 01 00 00 00 00 02 53 24
					//39 01 00 00 00 00 02 6A 00
					39 01 00 00 00 00 03 F0 A5 A5
				];
				qcom,mdss-dsi-aod-low-mode-command = [
					/* AOD 10nit */
					39 01 00 00 00 00 03 F0 5A 5A
					15 01 00 00 00 00 02 53 27
					//39 01 00 00 00 00 02 6A 00
					39 01 00 00 00 00 03 F0 A5 A5
				];
				qcom,mdss-dsi-seed-off-command = [
					/* SEED CRC OFF*/
					15 01 00 00 00 00 02 1C 00
					/* SEED CRC BYPASS */
					39 01 00 00 00 00 03 F0 5A 5A
					15 01 00 00 00 00 02 1D 01
					39 01 00 00 00 00 03 F0 A5 A5
				];
				qcom,mdss-dsi-seed-0-command = [
					/* SEED CRC Setting*/
					15 01 00 00 00 00 02 1C 05
					39 01 00 00 00 00 03 F0 5A 5A
					39 01 00 00 00 00 04 B0 00 01 1D
					/* SEED DCI-P3 Setting*/
					39 01 00 00 00 00 16 1D FF 00 00 00 FF 00 00 00 FF 00 FF FF FF 00 FF FF FF 00 FF FF FF
					15 01 00 00 00 00 02 1D 00
					39 01 00 00 00 00 03 F0 A5 A5
				];
				qcom,mdss-dsi-seed-1-command = [
					/* SEED CRC Setting*/
					15 01 00 00 00 00 02 1C 05
					39 01 00 00 00 00 03 F0 5A 5A
					39 01 00 00 00 00 04 B0 00 01 1D
					/* SEED DCI-P3 Setting*/
					39 01 00 00 00 00 16 1D FF 00 00 00 FF 00 00 00 FF 00 FF FF FF 00 FF FF FF 00 FF FF FF
					15 01 00 00 00 00 02 1D 00
					39 01 00 00 00 00 03 F0 A5 A5
				];
				qcom,mdss-dsi-seed-2-command = [
					/* SEED CRC Setting*/
					15 01 00 00 00 00 02 1C 05
					39 01 00 00 00 00 03 F0 5A 5A
					39 01 00 00 00 00 04 B0 00 01 1D
					/* SEED DCI-P3 Setting*/
					39 01 00 00 00 00 16 1D FF 00 00 00 FF 00 00 00 FF 00 FF FF FF 00 FF FF FF 00 FF FF FF
					15 01 00 00 00 00 02 1D 00
					39 01 00 00 00 00 03 F0 A5 A5
				];
				qcom,mdss-dsi-loading-effect-1-command = [
					39 00 00 00 00 00 03 F0 5A 5A
					39 00 00 00 00 00 04 B0 02 B6 1D
					39 00 00 00 00 00 02 1D 25
					39 00 00 00 00 00 04 B0 01 A5 1F
					39 00 00 00 00 00 09 1F E2 00 00 00 92 2C 6A 80
					39 00 00 00 00 00 04 B0 01 AD 1F
					39 00 00 00 00 00 07 1F 00 00 00 00 FF 90
					39 00 00 00 00 00 04 B0 01 B5 1F
					39 00 00 00 00 00 04 1F 49 00 10
					39 00 00 00 00 00 04 B0 01 BA 1F
					39 00 00 00 00 00 06 1F 05 FF 10 00 00
					39 00 00 00 00 00 04 B0 01 C1 1F
					39 00 00 00 00 00 05 1F 00 00 00 00
					39 00 00 00 00 00 04 B0 01 C5 1F
					39 00 00 00 00 00 05 1F 03 FF 21 3C
					39 01 00 00 00 00 03 F0 A5 A5
				];
				qcom,mdss-dsi-loading-effect-2-command = [
					39 00 00 00 00 00 03 F0 5A 5A
					39 00 00 00 00 00 04 B0 02 B6 1D
					39 00 00 00 00 00 02 1D 25
					39 00 00 00 00 00 04 B0 01 A5 1F
					39 00 00 00 00 00 09 1F E2 00 00 00 92 2C 6A 80
					39 00 00 00 00 00 04 B0 01 AD 1F
					39 00 00 00 00 00 07 1F 7D 64 7E 65 FF 90
					39 00 00 00 00 00 04 B0 01 B5 1F
					39 00 00 00 00 00 04 1F 49 00 10
					39 00 00 00 00 00 04 B0 01 BA 1F
					39 00 00 00 00 00 06 1F 05 FF 10 00 00
					39 00 00 00 00 00 04 B0 01 C1 1F
					39 00 00 00 00 00 05 1F 00 00 00 00
					39 00 00 00 00 00 04 B0 01 C5 1F
					39 00 00 00 00 00 05 1F 03 FF 21 3C
					39 01 00 00 00 00 03 F0 A5 A5
				];
				qcom,mdss-dsi-loading-effect-off-command = [
					39 00 00 00 00 00 03 F0 5A 5A
					39 00 00 00 00 00 04 B0 02 B6 1D
					39 00 00 00 00 00 02 1D 05
					39 01 00 00 00 00 03 F0 A5 A5
				];
				qcom,mdss-dsi-aod-hbm-on-command-state = "dsi_hs_mode";
				qcom,mdss-dsi-aod-hbm-off-command-state = "dsi_hs_mode";
				qcom,mdss-dsi-timing-switch-command-state = "dsi_hs_mode";
				qcom,mdss-dsi-on-command-state = "dsi_lp_mode";
				qcom,mdss-dsi-off-command-state = "dsi_hs_mode";
				qcom,mdss-dsi-seed-off-command-state = "dsi_hs_mode";
				qcom,mdss-dsi-seed-0-command-state = "dsi_hs_mode";
				qcom,mdss-dsi-seed-1-command-state = "dsi_hs_mode";
				qcom,mdss-dsi-seed-2-command-state = "dsi_hs_mode";
				qcom,mdss-dsi-loading-effect-1-command-state = "dsi_hs_mode";
				qcom,mdss-dsi-loading-effect-2-command-state = "dsi_hs_mode";
				qcom,mdss-dsi-loading-effect-off-command-state = "dsi_hs_mode";
				qcom,mdss-dsi-hbm-on-command-state = "dsi_hs_mode";
				qcom,mdss-dsi-hbm-off-command-state = "dsi_hs_mode";
				qcom,mdss-dsi-aor-restore-command-state = "dsi_hs_mode";

				qcom,compression-mode = "dsc";
				qcom,lm-split = <540 540>;
				qcom,mdss-dsc-encoders = <2>;
				qcom,mdss-dsc-slice-height = <36>;
				qcom,mdss-dsc-slice-width = <540>;
				qcom,mdss-dsc-slice-per-pkt = <2>;
				qcom,mdss-dsc-bit-per-component = <10>;
				qcom,mdss-dsc-bit-per-pixel = <8>;
				qcom,mdss-dsc-block-prediction-enable;
				qcom,mdss-dsi-panel-id1-command-state = "dsi_lp_mode";
				qcom,mdss-dsi-panel-read-register-open-state = "dsi_lp_mode";
				qcom,mdss-dsi-panel-read-register-close-state = "dsi_lp_mode";
			};
			timing@sdc_fhd_60{
				//qcom,mdss-mdp-transfer-time-us = <7700>;
				qcom,mdss-dsi-panel-jitter = <0x4 0x1>;
				qcom,mdss-dsc-scr-version = <0x1>;
				qcom,mdss-dsi-timing-default;
				qcom,mdss-dsi-panel-framerate = <60>;
				qcom,mdss-dsi-panel-clockrate = <825600000>;
				qcom,mdss-dsi-panel-width = <1080>;
				qcom,mdss-dsi-panel-height = <2412>;

				qcom,mdss-dsi-h-front-porch = <64>;
				qcom,mdss-dsi-h-back-porch = <48>;
				qcom,mdss-dsi-h-pulse-width = <8>;
				qcom,mdss-dsi-h-sync-skew = <0>;
				qcom,mdss-dsi-v-back-porch = <12>;
				qcom,mdss-dsi-v-front-porch = <8>;
				qcom,mdss-dsi-v-pulse-width = <4>;
				qcom,mdss-dsi-h-sync-pulse = <0>;

				qcom,mdss-dsi-h-left-border = <0>;
				qcom,mdss-dsi-h-right-border = <0>;
				qcom,mdss-dsi-v-top-border = <0>;
				qcom,mdss-dsi-v-bottom-border = <0>;

				qcom,dsi-select-clocks = "mux_byte_clk0", "mux_pixel_clk0";

				oplus,fod-on-vblank = <0>;
				oplus,fod-off-vblank = <0>;
				qcom,mdss-dsi-panel-read-register-open-command = [
					39 01 00 00 00 00 03 F0 5A 5A
					];
				qcom,mdss-dsi-panel-id1-command = [
					06 01 00 00 00 00 01 E9
					];
				qcom,mdss-dsi-panel-read-register-close-command = [
					39 01 00 00 00 00 03 F0 A5 A5
					];
				qcom,mdss-dsi-timing-switch-command = [
					/* CASET/PASET Setting */
					39 00 00 00 00 00 05 2A 00 00 04 37
					39 00 00 00 00 00 05 2B 00 00 09 6B
					/* Scaler Setting */
					39 00 00 00 00 00 03 F0 5A 5A
					15 00 00 00 00 00 02 C3 89
					39 00 00 00 00 00 04 B0 00 24 C3
					39 00 00 00 00 00 12 C3 FD 00 FD 00 FD 00 FD 00 FD 00 FD 00 FD 00 FD 00 FD
					39 00 00 00 00 00 04 B0 00 3A C3
					39 00 00 00 00 00 12 C3 B0 00 B0 00 B0 00 B0 00 B0 00 B0 00 B0 00 B0 00 B0
					39 00 00 00 00 00 04 B0 00 50 C3
					39 00 00 00 00 00 12 C3 43 00 43 00 43 00 43 00 43 00 43 00 43 00 43 00 43
					39 00 00 00 00 00 04 B0 00 61 C3
					39 00 00 00 00 00 17 C3 CC CC CC CC C0 FE 00 FE 00 FE 00 FE 00 FE 00 FE 00 FE 00 FE 00 FE
					39 00 00 00 00 00 03 F0 A5 A5

					/* OPLUS ADFR OFF */
					39 00 00 00 00 00 03 F0 5A 5A
					39 00 00 00 00 00 03 FC 5A 5A
					15 00 00 00 00 00 02 B9 00						/* TP shift fixed */
					39 00 00 00 00 00 04 B0 00 02 60
					15 00 00 00 00 00 02 60 00						/* OPLUS ADFR OFF */
					39 00 00 00 00 00 03 F2 00 01					/* 0x01,0x00:ADFR ON setting 0x00,0x01:ADFR OFF Setting */
					15 00 00 00 00 00 02 F7 0F
					39 00 00 00 00 00 03 FC A5 A5
					39 00 00 00 00 00 03 F0 A5 A5

					/* TSP_HSYNC(SYNC1) Fixed Setting */
					39 00 00 00 00 00 03 F0 5A 5A
					39 00 00 00 00 00 04 B0 00 22 B9
					39 00 00 00 00 00 03 B9 A1 B1						/* TSP_SYNC1 = TSP_VSYNC ,  TSP_SYNC2 = TSP_HSYNC */
					39 00 00 00 00 00 04 B0 00 3A B9
					15 00 00 00 00 00 02 B9 05						/* TSP_VSYNC Fixed TE 02:120 03:90 05:60 */
					39 00 00 00 00 00 04 B0 00 26 B9
					39 00 00 00 00 00 03 B9 00 00
					15 00 00 00 00 00 02 F7 0F
					39 00 00 00 00 00 03 F0 A5 A5
					/* TSP_SYNC3 Fixed Setting */
					39 00 00 00 00 00 03 F0 5A 5A
					39 00 00 00 00 00 04 B0 00 24 B9
					15 00 00 00 00 00 02 B9 21
					39 00 00 00 00 00 04 B0 00 38 B9
					15 00 00 00 00 00 02 B9 05						/* TSP_VSYNC Fixed TE 02:120 03:90 05:60 */
					39 00 00 00 00 00 04 B0 00 2A B9
					39 00 00 00 00 00 03 B9 00 00
					15 00 00 00 00 00 02 F7 0F
					39 00 00 00 00 00 03 F0 A5 A5

					/* 60hz Transition */
					39 00 00 00 00 00 03 F0 5A 5A
					39 00 00 00 00 00 04 B0 00 16 F2
					39 00 00 00 00 00 03 F2 1B 50					/* 0x1B,0x50:120hz 0x24,0x70:90hz */
					39 00 00 00 00 00 03 BD 21 02					/* 0x21,0x02:120hz 0x21,0x03:90hz */
					15 00 00 00 00 00 02 60 01						/* 0x00:120hz 0x08:90hz 0x01:60hz */
					39 00 00 00 00 00 04 B0 00 10 BD
					15 00 00 00 00 00 02 BD 00						/* HOP force off */
					15 00 00 00 00 00 02 F7 0F
					39 01 00 00 00 00 03 F0 A5 A5
				];
				qcom,mdss-dsi-on-command = [
					/* DSC Setting */
					39 01 00 00 00 00 5A 9E 11
					00 00 AB 30 80 09 6C 04 38
					00 24 02 1C 02 1C 02 00 02
					3B 00 20 03 35 00 07 00 0E
					03 34 02 D4 18 00 10 F0 07
					10 20 00 06 0F 0F 33 0E 1C
					2A 38 46 54 62 69 70 77 79
					7B 7D 7E 02 02 22 00 2A 40
					2A BE 3A FC 3A FA 3A F8 3B
					38 3B 78 3B B6 4B B6 4B F4
					4B F4 6C 34 84 74 00
					15 01 00 00 00 00 02 9D 01

					/* Sleep Out(11h) */
					05 01 00 00 05 00 01 11

					/* TSP_HSYNC(SYNC1) Fixed Setting */
					39 00 00 00 00 00 03 F0 5A 5A
					39 00 00 00 00 00 04 B0 00 22 B9
					39 00 00 00 00 00 03 B9 A1 B1						/* TSP_SYNC1 = TSP_VSYNC ,  TSP_SYNC2 = TSP_HSYNC */
					39 00 00 00 00 00 04 B0 00 3A B9
					15 00 00 00 00 00 02 B9 05						/* TSP_VSYNC Fixed TE 02:120 03:90 05:60 */
					39 00 00 00 00 00 04 B0 00 26 B9
					39 00 00 00 00 00 03 B9 00 00
					15 00 00 00 00 00 02 F7 0F
					39 00 00 00 00 00 03 F0 A5 A5
					/* TSP_SYNC3 Fixed Setting */
					39 00 00 00 00 00 03 F0 5A 5A
					39 00 00 00 00 00 04 B0 00 24 B9
					15 00 00 00 00 00 02 B9 21
					39 00 00 00 00 00 04 B0 00 38 B9
					15 00 00 00 00 00 02 B9 05						/* TSP_VSYNC Fixed TE 02:120 03:90 05:60 */
					39 00 00 00 00 00 04 B0 00 2A B9
					39 00 00 00 00 00 03 B9 00 00
					15 00 00 00 00 00 02 F7 0F
					39 01 00 00 78 00 03 F0 A5 A5
					/* 60hz Transition */
					39 00 00 00 00 00 03 F0 5A 5A
					39 00 00 00 00 00 04 B0 00 16 F2
					39 00 00 00 00 00 03 F2 1B 50					/* 0x1B,0x50:120hz 0x24,0x70:90hz */
					39 00 00 00 00 00 03 BD 21 02					/* 0x21,0x02:120hz 0x21,0x03:90hz */
					15 00 00 00 00 00 02 60 01						/* 0x00:120hz 0x08:90hz 0x01:60hz */
					39 00 00 00 00 00 04 B0 00 10 BD
					15 00 00 00 00 00 02 BD 00						/* HOP force off */
					15 00 00 00 00 00 02 F7 0F
					39 01 00 00 00 00 03 F0 A5 A5

					/* Common Setting */
					39 00 00 00 00 00 03 F0 5A 5A
					39 00 00 00 00 00 03 F2 00 01					/* FQ_CON Setting */
					39 01 00 00 00 00 03 F0 A5 A5
					/* TE(Vsync) ON */
					39 00 00 00 00 00 03 F0 5A 5A
					15 00 00 00 00 00 02 35 00
					15 00 00 00 00 00 02 B9 00
					39 01 00 00 00 00 03 F0 A5 A5
					/* CASET/PASET Setting */
					39 00 00 00 00 00 05 2A 00 00 04 37
					39 01 00 00 00 00 05 2B 00 00 09 6B
					/* Loading effect compensation Control */
					39 00 00 00 00 00 03 F0 5A 5A
					39 00 00 00 00 00 04 B0 02 B6 1D
					15 00 00 00 00 00 02 1D 05
					39 01 00 00 00 00 03 F0 A5 A5
					/* Scaler Setting */
					39 00 00 00 00 00 03 F0 5A 5A
					15 00 00 00 00 00 02 C3 89
					39 00 00 00 00 00 04 B0 00 24 C3
					39 00 00 00 00 00 12 C3 FD 00 FD 00 FD 00 FD 00 FD 00 FD 00 FD 00 FD 00 FD
					39 00 00 00 00 00 04 B0 00 3A C3
					39 00 00 00 00 00 12 C3 B0 00 B0 00 B0 00 B0 00 B0 00 B0 00 B0 00 B0 00 B0
					39 00 00 00 00 00 04 B0 00 50 C3
					39 00 00 00 00 00 12 C3 43 00 43 00 43 00 43 00 43 00 43 00 43 00 43 00 43
					39 00 00 00 00 00 04 B0 00 61 C3
					39 00 00 00 00 00 17 C3 CC CC CC CC C0 FE 00 FE 00 FE 00 FE 00 FE 00 FE 00 FE 00 FE 00 FE
					39 01 00 00 00 00 03 F0 A5 A5

					/* Brightness Control */
					39 00 00 00 00 00 03 F0 5A 5A
					39 00 00 00 00 00 04 B0 00 0D 63
					15 00 00 00 00 00 02 63 01						/* Dimming Setting */
					39 00 00 00 00 00 04 B0 00 0C 63
					15 00 00 00 00 00 02 63 20
					39 00 00 00 00 00 03 F0 A5 A5
					15 00 00 00 00 00 02 53 28
					15 01 00 00 00 00 02 F7 0F
					/* Pre-charge setting */
					39 01 00 00 00 00 03 F0 5A 5A
					39 01 00 00 00 00 04 B0 00 2b F6
					39 01 00 00 00 00 04 F6 60 63 69
					39 01 00 00 00 00 02 F7 0F
					39 01 00 00 00 00 03 F0 A5 A5
					/* OPEC ON */
					39 00 00 00 00 00 03 F0 5A 5A
					39 00 00 00 00 00 04 B0 00 56 1F
					39 00 00 00 00 00 11 1F 01 05 01 06 03 24 06 c0 06 c1 0d af 0d b0 1b b0
					39 00 00 00 00 00 04 B0 00 6A 1F
					39 00 00 00 00 00 1D 1F 01 05 03 24 04 4c 05 78 06 c0 08 34 09 c4 0b 54 0d af 0e 10 0e d8 0f a0 10 68 11 30
					39 00 00 00 00 00 04 B0 00 52 1F
					39 00 00 00 00 00 02 1F 02
					39 00 00 00 00 00 04 B0 00 54 1F
					39 00 00 00 00 00 02 1F 00
					39 01 00 00 00 00 03 F0 A5 A5
					/* ACL Mode */
					39 00 00 00 00 00 03 F0 5A 5A
					15 00 00 00 00 00 02 55 00
					39 01 00 00 00 00 03 F0 A5 A5

					/* Display On */
					//05 01 00 00 00 00 01 29
				];
				qcom,mdss-dsi-post-on-backlight = [
					/* Display On */
					05 01 00 00 00 00 01 29
				];
				qcom,mdss-dsi-off-command=[
					05 01 00 00 0A 00 02 28 00
					05 01 00 00 78 00 02 10 00
				];
				qcom,mdss-dsi-lp1-command = [
					/* Panle OFF */
					05 01 00 00 11 00 01 28
					/* AOD Mode ON Setting */
					39 01 00 00 00 00 03 F0 5A 5A
					15 01 00 00 00 00 02 53 24
					//15 01 00 00 00 00 02 49 01
					39 01 00 00 14 00 03 F0 A5 A5
					05 01 00 00 00 00 01 29
				];
				qcom,mdss-dsi-nolp-command = [
					/* AOD OFF */
					39 01 00 00 00 00 03 F0 5A 5A
					15 01 00 00 00 00 02 53 28
					//15 01 00 00 00 00 02 49 02
					39 01 00 00 00 00 03 F0 A5 A5

					/* ELVSS DIM OFF  */
					39 01 00 00 00 00 03 F0 5A 5A
					39 01 00 00 00 00 04 B0 00 0C 63
					15 01 00 00 00 00 02 63 00
					39 01 00 00 00 00 03 F0 A5 A5

					/* HBM OFF Mode */
					39 01 00 00 00 00 02 53 20
					//39 01 00 00 00 00 03 51 07 FF
				];
				qcom,mdss-dsi-aod-hbm-on-command = [
					/* Loading OFF */
					39 00 00 00 00 00 03 F0 5A 5A
					39 00 00 00 00 00 04 B0 02 B6 1D
					39 00 00 00 00 00 02 1D 05
					39 01 00 00 00 00 03 F0 A5 A5
					/* AOD OFF */
					39 00 00 00 00 00 03 F0 5A 5A
					39 00 00 00 00 00 02 53 28
					39 01 00 00 00 00 03 F0 A5 A5
					/* Hbm ON */
					15 01 00 00 00 00 02 53 E0
					39 01 00 00 00 00 03 51 0F 1F
				];
				qcom,mdss-dsi-aod-hbm-off-command = [
					/* HBM OFF Mode */
					39 01 00 00 00 00 02 53 20
					//39 01 00 00 00 00 03 51 07 FF
					/* AOD 50nit */
					39 01 00 00 00 00 03 F0 5A 5A
					15 01 00 00 00 00 02 53 24
					//39 01 00 00 00 00 02 6A 00
					15 01 00 00 00 00 02 F7 0F
					//15 01 00 00 00 00 02 49 01
					39 01 00 00 00 00 03 F0 A5 A5
				];
				/*** pvt commond for ID1 >= 05 ***/
				qcom,mdss-dsi-lp1-pvt-command = [
					05 01 00 00 11 00 01 28
					/* AOD Mode ON Setting */
					39 01 00 00 00 00 03 F0 5A 5A
					15 01 00 00 00 00 02 53 24
					39 01 00 00 24 00 03 F0 A5 A5
					05 01 00 00 00 00 01 29
				];
				qcom,mdss-dsi-nolp-pvt-command = [
					/* AOD OFF */
					39 01 00 00 00 00 03 F0 5A 5A
					15 01 00 00 00 00 02 53 28
					39 01 00 00 00 00 03 F0 A5 A5
					/* HBM OFF Mode */
					39 01 00 00 00 00 02 53 20
					//39 01 00 00 00 00 03 51 07 FF
				];
				qcom,mdss-dsi-aod-hbm-on-pvt-command = [
					/* Loading OFF */
					39 00 00 00 00 00 03 F0 5A 5A
					39 00 00 00 00 00 04 B0 02 B6 1D
					39 00 00 00 00 00 02 1D 05
					39 01 00 00 00 00 03 F0 A5 A5
					/* AOD OFF */
					39 00 00 00 00 00 03 F0 5A 5A
					39 00 00 00 00 00 02 53 28
					39 01 00 00 00 00 03 F0 A5 A5
					/* AOR 1.6% */
					39 00 00 00 00 00 03 F0 5A 5A
					39 00 00 00 00 00 04 B0 00 01 BD
					39 00 00 00 00 00 02 BD 02
					39 00 00 00 00 00 04 B0 02 b9 65
					39 00 00 00 00 00 07 65 00 AC 00 AC 00 AC
					39 00 00 00 00 00 02 F7 0F
					39 01 00 00 11 00 03 F0 A5 A5
					/* Hbm ON */
					15 01 00 00 11 00 02 53 E0
					39 01 00 00 00 00 03 51 0F 1F
				];
				qcom,mdss-dsi-aod-hbm-off-pvt-command = [
					/* HBM OFF Mode */
					39 01 00 00 00 00 02 53 20
					//39 01 00 00 00 00 03 51 07 FF
					/* AOD ON */
					39 01 00 00 00 00 03 F0 5A 5A
					15 01 00 00 00 00 02 53 24
					39 01 00 00 00 00 03 F0 A5 A5
				];
				qcom,mdss-dsi-hbm-off-command = [
					/* HBM OFF Mode */
					39 00 00 00 00 00 03 f0 5a 5a
					39 00 00 00 00 00 04 b0 00 0c 63
					15 00 00 00 00 00 02 63 20
					39 00 00 00 00 00 03 f0 a5 a5
					39 01 00 00 00 00 02 53 28
				];
				qcom,mdss-dsi-hbm-on-command = [
					/* elvss dim off + dly on */
					39 00 00 00 00 00 03 f0 5a 5a
					39 00 00 00 00 00 04 b0 00 0c 63
					15 00 00 00 00 00 02 63 20
					39 00 00 00 00 00 03 f0 a5 a5
					/* Loading OFF */
					39 00 00 00 00 00 03 f0 5a 5a
					39 00 00 00 00 00 04 b0 02 b6 1d
					39 00 00 00 00 00 02 1d 05
					39 00 00 00 00 00 03 f0 a5 a5
					/* aor 1.6% */
					39 00 00 00 00 00 03 f0 5a 5a
					39 00 00 00 00 00 04 b0 00 01 bd
					39 00 00 00 00 00 02 bd 02
					39 00 00 00 00 00 04 b0 02 b9 65
					39 00 00 00 00 00 07 65 00 ac 00 ac 00 ac
					39 00 00 00 00 00 02 f7 0f
					39 00 00 00 00 00 03 f0 a5 a5
					15 01 00 00 09 00 02 53 e0
					39 01 00 00 00 00 03 51 0F 1F
				];
				qcom,mdss-dsi-normal-hbm-on-command = [
					/* elvss dim off + dly on */
					39 00 00 00 00 00 03 f0 5a 5a
					39 00 00 00 00 00 04 b0 00 0c 63
					15 00 00 00 00 00 02 63 20
					39 00 00 00 00 00 03 f0 a5 a5
					/* Loading OFF */
					39 00 00 00 00 00 03 f0 5a 5a
					39 00 00 00 00 00 04 b0 02 b6 1d
					39 00 00 00 00 00 02 1d 05
					39 00 00 00 00 00 03 f0 a5 a5
					/* aor 1.6% */
					39 00 00 00 00 00 03 f0 5a 5a
					39 00 00 00 00 00 04 b0 00 01 bd
					39 00 00 00 00 00 02 bd 02
					39 00 00 00 00 00 04 b0 02 b9 65
					39 00 00 00 00 00 07 65 00 ac 00 ac 00 ac
					39 00 00 00 00 00 02 f7 0f
					39 00 00 00 00 00 03 f0 a5 a5
					15 01 00 00 09 00 02 53 e0
					39 01 00 00 00 00 03 51 0F 1F
				];
				qcom,mdss-dsi-hbm-enter-switch-command = [
					15 01 00 00 00 00 02 53 E0
				];
				qcom,mdss-dsi-hbm-exit-switch-command = [
					39 01 00 00 00 00 02 53 20
				];
				qcom,mdss-dsi-aor-restore-command = [
					/* AOR 16% */
					39 00 00 00 00 00 03 f0 5a 5a
					39 00 00 00 00 00 04 b0 00 01 bd
					39 00 00 00 00 00 02 bd 02
					39 00 00 00 00 00 04 b0 02 b9 65
					39 00 00 00 00 00 07 65 01 5e 01 5e 01 5e
					39 00 00 00 00 00 02 f7 0f
					39 01 00 00 00 00 03 f0 a5 a5
				];
				qcom,mdss-dsi-aod-high-mode-command = [
					/* AOD 50nit */
					39 01 00 00 00 00 03 F0 5A 5A
					15 01 00 00 00 00 02 53 24
					39 01 00 00 00 00 03 F0 A5 A5
				];
				qcom,mdss-dsi-aod-low-mode-command = [
					/* AOD 10nit */
					39 01 00 00 00 00 03 F0 5A 5A
					15 01 00 00 00 00 02 53 27
					39 01 00 00 00 00 03 F0 A5 A5
				];
				qcom,mdss-dsi-seed-off-command = [
					/* SEED CRC OFF*/
					15 01 00 00 00 00 02 1C 00
					/* SEED CRC BYPASS */
					39 01 00 00 00 00 03 F0 5A 5A
					15 01 00 00 00 00 02 1D 01
					39 01 00 00 00 00 03 F0 A5 A5
				];
				qcom,mdss-dsi-seed-0-command = [
					/* SEED CRC Setting*/
					15 01 00 00 00 00 02 1C 05
					39 01 00 00 00 00 03 F0 5A 5A
					39 01 00 00 00 00 04 B0 00 01 1D
					/* SEED DCI-P3 Setting*/
					39 01 00 00 00 00 16 1D FF 00 00 00 FF 00 00 00 FF 00 FF FF FF 00 FF FF FF 00 FF FF FF
					15 01 00 00 00 00 02 1D 00
					39 01 00 00 00 00 03 F0 A5 A5
				];
				qcom,mdss-dsi-seed-1-command = [
					/* SEED CRC Setting*/
					15 01 00 00 00 00 02 1C 05
					39 01 00 00 00 00 03 F0 5A 5A
					39 01 00 00 00 00 04 B0 00 01 1D
					/* SEED DCI-P3 Setting*/
					39 01 00 00 00 00 16 1D FF 00 00 00 FF 00 00 00 FF 00 FF FF FF 00 FF FF FF 00 FF FF FF
					15 01 00 00 00 00 02 1D 00
					39 01 00 00 00 00 03 F0 A5 A5
				];
				qcom,mdss-dsi-seed-2-command = [
					/* SEED CRC Setting*/
					15 01 00 00 00 00 02 1C 05
					39 01 00 00 00 00 03 F0 5A 5A
					39 01 00 00 00 00 04 B0 00 01 1D
					/* SEED DCI-P3 Setting*/
					39 01 00 00 00 00 16 1D FF 00 00 00 FF 00 00 00 FF 00 FF FF FF 00 FF FF FF 00 FF FF FF
					15 01 00 00 00 00 02 1D 00
					39 01 00 00 00 00 03 F0 A5 A5
				];
				qcom,mdss-dsi-loading-effect-1-command = [
					39 00 00 00 00 00 03 F0 5A 5A
					39 00 00 00 00 00 04 B0 02 B6 1D
					39 00 00 00 00 00 02 1D 25
					39 00 00 00 00 00 04 B0 01 A5 1F
					39 00 00 00 00 00 09 1F E2 00 00 00 92 2C 6A 80
					39 00 00 00 00 00 04 B0 01 AD 1F
					39 00 00 00 00 00 07 1F 00 00 00 00 FF 90
					39 00 00 00 00 00 04 B0 01 B5 1F
					39 00 00 00 00 00 04 1F 49 00 10
					39 00 00 00 00 00 04 B0 01 BA 1F
					39 00 00 00 00 00 06 1F 05 FF 10 00 00
					39 00 00 00 00 00 04 B0 01 C1 1F
					39 00 00 00 00 00 05 1F 00 00 00 00
					39 00 00 00 00 00 04 B0 01 C5 1F
					39 00 00 00 00 00 05 1F 03 FF 21 3C
					39 01 00 00 00 00 03 F0 A5 A5
				];
				qcom,mdss-dsi-loading-effect-2-command = [
					39 00 00 00 00 00 03 F0 5A 5A
					39 00 00 00 00 00 04 B0 02 B6 1D
					39 00 00 00 00 00 02 1D 25
					39 00 00 00 00 00 04 B0 01 A5 1F
					39 00 00 00 00 00 09 1F E2 00 00 00 92 2C 6A 80
					39 00 00 00 00 00 04 B0 01 AD 1F
					39 00 00 00 00 00 07 1F 7D 64 7E 65 FF 90
					39 00 00 00 00 00 04 B0 01 B5 1F
					39 00 00 00 00 00 04 1F 49 00 10
					39 00 00 00 00 00 04 B0 01 BA 1F
					39 00 00 00 00 00 06 1F 05 FF 10 00 00
					39 00 00 00 00 00 04 B0 01 C1 1F
					39 00 00 00 00 00 05 1F 00 00 00 00
					39 00 00 00 00 00 04 B0 01 C5 1F
					39 00 00 00 00 00 05 1F 03 FF 21 3C
					39 01 00 00 00 00 03 F0 A5 A5
				];
				qcom,mdss-dsi-loading-effect-off-command = [
					39 00 00 00 00 00 03 F0 5A 5A
					39 00 00 00 00 00 04 B0 02 B6 1D
					39 00 00 00 00 00 02 1D 05
					39 01 00 00 00 00 03 F0 A5 A5
				];
				qcom,mdss-dsi-aod-hbm-on-command-state = "dsi_hs_mode";
				qcom,mdss-dsi-aod-hbm-off-command-state = "dsi_hs_mode";
				qcom,mdss-dsi-timing-switch-command-state = "dsi_hs_mode";
				qcom,mdss-dsi-on-command-state = "dsi_lp_mode";
				qcom,mdss-dsi-off-command-state = "dsi_hs_mode";
				qcom,mdss-dsi-seed-off-command-state = "dsi_hs_mode";
				qcom,mdss-dsi-seed-0-command-state = "dsi_hs_mode";
				qcom,mdss-dsi-seed-1-command-state = "dsi_hs_mode";
				qcom,mdss-dsi-seed-2-command-state = "dsi_hs_mode";
				qcom,mdss-dsi-loading-effect-1-command-state = "dsi_hs_mode";
				qcom,mdss-dsi-loading-effect-2-command-state = "dsi_hs_mode";
				qcom,mdss-dsi-loading-effect-off-command-state = "dsi_hs_mode";
				qcom,mdss-dsi-hbm-on-command-state = "dsi_hs_mode";
				qcom,mdss-dsi-hbm-off-command-state = "dsi_hs_mode";
				qcom,mdss-dsi-aor-restore-command-state = "dsi_hs_mode";

				qcom,lm-split = <540 540>;
				qcom,compression-mode = "dsc";
				qcom,mdss-dsc-encoders = <2>;
				qcom,mdss-dsc-slice-height = <36>;
				qcom,mdss-dsc-slice-width = <540>;
				qcom,mdss-dsc-slice-per-pkt = <2>;
				qcom,mdss-dsc-bit-per-component = <10>;
				qcom,mdss-dsc-bit-per-pixel = <8>;
				qcom,mdss-dsc-block-prediction-enable;
				qcom,mdss-dsi-panel-id1-command-state = "dsi_lp_mode";
				qcom,mdss-dsi-panel-read-register-open-state = "dsi_lp_mode";
				qcom,mdss-dsi-panel-read-register-close-state = "dsi_lp_mode";
			};
			timing@sdc_wqhd_120{
				qcom,mdss-dsi-panel-jitter = <0x4 0x1>;
				qcom,mdss-dsc-scr-version = <0x1>;
				qcom,mdss-dsi-timing-default;
				qcom,mdss-mdp-transfer-time-us = <7700>;
				qcom,mdss-dsi-panel-framerate = <120>;
				qcom,mdss-dsi-panel-clockrate = <1372000000>;
				qcom,mdss-dsi-panel-width = <1440>;
				qcom,mdss-dsi-panel-height = <3216>;

				qcom,mdss-dsi-h-front-porch = <100>;
				qcom,mdss-dsi-h-back-porch = <48>;
				qcom,mdss-dsi-h-pulse-width = <12>;
				qcom,mdss-dsi-h-sync-skew = <0>;
				qcom,mdss-dsi-v-back-porch = <8>;
				qcom,mdss-dsi-v-front-porch = <8>;
				qcom,mdss-dsi-v-pulse-width = <8>;
				qcom,mdss-dsi-h-sync-pulse = <0>;

				qcom,mdss-dsi-h-left-border = <0>;
				qcom,mdss-dsi-h-right-border = <0>;
				qcom,mdss-dsi-v-top-border = <0>;
				qcom,mdss-dsi-v-bottom-border = <0>;

				qcom,dsi-select-clocks = "mux_byte_clk0", "mux_pixel_clk0";

				oplus,fod-on-vblank = <0>;
				oplus,fod-off-vblank = <1>;
				qcom,mdss-dsi-panel-read-register-open-command = [
					39 01 00 00 00 00 03 F0 5A 5A
					];
				qcom,mdss-dsi-panel-id1-command = [
					06 01 00 00 00 00 01 E9
					];
				qcom,mdss-dsi-panel-read-register-close-command = [
					39 01 00 00 00 00 03 F0 A5 A5
					];
				qcom,mdss-dsi-timing-switch-command = [
					/* CASET/PASET Setting */
					39 00 00 00 00 00 05 2A 00 00 05 9F
					39 00 00 00 00 00 05 2B 00 00 0C 8F
					/* Scaler Setting */
					39 00 00 00 00 00 03 F0 5A 5A
					15 00 00 00 00 00 02 C3 00
					39 00 00 00 00 00 03 F0 A5 A5

					/* OPLUS ADFR OFF */
					39 00 00 00 00 00 03 F0 5A 5A
					39 00 00 00 00 00 03 FC 5A 5A
					15 00 00 00 00 00 02 B9 00						/* TP shift fixed */
					39 00 00 00 00 00 04 B0 00 02 60
					15 00 00 00 00 00 02 60 00						/* OPLUS ADFR OFF */
					39 00 00 00 00 00 03 F2 00 01					/* 0x01,0x00:ADFR ON setting 0x00,0x01:ADFR OFF Setting */
					15 00 00 00 00 00 02 F7 0F
					39 00 00 00 00 00 03 FC A5 A5
					39 00 00 00 00 00 03 F0 A5 A5

					/* TSP_VSYNC(SYNC1) Fixed Setting */
					39 00 00 00 00 00 03 F0 5A 5A
					39 00 00 00 00 00 04 B0 00 22 B9
					39 00 00 00 00 00 03 B9 A1 B1						/* TSP_SYNC1 = TSP_VSYNC ,  TSP_SYNC2 = TSP_HSYNC */
					39 00 00 00 00 00 04 B0 00 3A B9
					15 00 00 00 00 00 02 B9 02						/* TSP_VSYNC Fixed TE 02:120 03:90 05:60 */
					39 00 00 00 00 00 04 B0 00 26 B9
					39 00 00 00 00 00 03 B9 00 00
					15 00 00 00 00 00 02 F7 0F
					39 00 00 00 00 00 03 F0 A5 A5
					/* TSP_SYNC3 Fixed Setting */
					39 00 00 00 00 00 03 F0 5A 5A
					39 00 00 00 00 00 04 B0 00 24 B9
					15 00 00 00 00 00 02 B9 21
					39 00 00 00 00 00 04 B0 00 38 B9
					15 00 00 00 00 00 02 B9 02						/* TSP_VSYNC Fixed TE 02:120 03:90 05:60 */
					39 00 00 00 00 00 04 B0 00 2A B9
					39 00 00 00 00 00 03 B9 00 00
					15 00 00 00 00 00 02 F7 0F
					39 00 00 00 00 00 03 F0 A5 A5

					/* 120hz Transition */
					39 00 00 00 00 00 03 F0 5A 5A
					39 00 00 00 00 00 04 B0 00 16 F2
					39 00 00 00 00 00 03 F2 1B 50					/* 0x1B,0x50:120hz 0x24,0x70:90hz */
					39 00 00 00 00 00 03 BD 21 02					/* 0x21,0x02:120hz 0x21,0x03:90hz */
					15 00 00 00 00 00 02 60 00						/* 0x00:120hz 0x08:90hz 0x01:60hz */
					39 00 00 00 00 00 04 B0 00 10 BD
					15 00 00 00 00 00 02 BD 10						/* 0x00:1frame 0x10:2frame 0x20:3frame */
					15 00 00 00 00 00 02 F7 0F
					39 01 00 00 00 00 03 F0 A5 A5
				];
				qcom,mdss-dsi-on-command = [
					/* DSC Setting */
					39 01 00 00 00 00 5A 9E 11
					00 00 AB 30 80 0C 90 05 A0
					00 18 02 D0 02 D0 02 00 02
					86 00 20 02 83 00 0A 00 0D
					04 86 03 2E 18 00 10 F0 07
					10 20 00 06 0F 0F 33 0E 1C
					2A 38 46 54 62 69 70 77 79
					7B 7D 7E 02 02 22 00 2A 40
					2A BE 3A FC 3A FA 3A F8 3B
					38 3B 78 3B B6 4B B6 4B F4
					4B F4 6C 34 84 74 00
					15 01 00 00 00 00 02 9D 01

					/* Sleep Out(11h) */
					05 01 00 00 05 00 01 11

					/* TSP_VSYNC(SYNC1) Fixed Setting */
					39 00 00 00 00 00 03 F0 5A 5A
					39 00 00 00 00 00 04 B0 00 22 B9
					39 00 00 00 00 00 03 B9 A1 B1						/* TSP_SYNC1 = TSP_VSYNC ,  TSP_SYNC2 = TSP_HSYNC */
					39 00 00 00 00 00 04 B0 00 3A B9
					15 00 00 00 00 00 02 B9 02						/* TSP_VSYNC Fixed TE 02:120 03:90 05:60 */
					39 00 00 00 00 00 04 B0 00 26 B9
					39 00 00 00 00 00 03 B9 00 00
					15 00 00 00 00 00 02 F7 0F
					39 01 00 00 00 00 03 F0 A5 A5
					/* TSP_SYNC3 Fixed Setting */
					39 00 00 00 00 00 03 F0 5A 5A
					39 00 00 00 00 00 04 B0 00 24 B9
					15 00 00 00 00 00 02 B9 21
					39 00 00 00 00 00 04 B0 00 38 B9
					15 00 00 00 00 00 02 B9 02						/* TSP_VSYNC Fixed TE 02:120 03:90 05:60 */
					39 00 00 00 00 00 04 B0 00 2A B9
					39 00 00 00 00 00 03 B9 00 00
					15 00 00 00 00 00 02 F7 0F
					39 01 00 00 78 00 03 F0 A5 A5
					/* 120hz Transition */
					39 00 00 00 00 00 03 F0 5A 5A
					39 00 00 00 00 00 04 B0 00 16 F2
					39 00 00 00 00 00 03 F2 1B 50					/* 0x1B,0x50:120hz 0x24,0x70:90hz */
					39 00 00 00 00 00 03 BD 21 02					/* 0x21,0x02:120hz 0x21,0x03:90hz */
					15 00 00 00 00 00 02 60 00						/* 0x00:120hz 0x08:90hz 0x01:60hz */
					39 00 00 00 00 00 04 B0 00 10 BD
					15 00 00 00 00 00 02 BD 10						/* 0x00:1frame 0x10:2frame 0x20:3frame */
					15 00 00 00 00 00 02 F7 0F
					39 01 00 00 00 00 03 F0 A5 A5


					/* Common Setting */
					39 00 00 00 00 00 03 F0 5A 5A
					39 00 00 00 00 00 03 F2 00 01					/* FQ_CON Setting */
					39 01 00 00 00 00 03 F0 A5 A5
					/* TE(Vsync) ON */
					39 00 00 00 00 00 03 F0 5A 5A
					15 00 00 00 00 00 02 35 00
					15 00 00 00 00 00 02 B9 00
					39 01 00 00 00 00 03 F0 A5 A5
					/* CASET/PASET Setting */
					39 01 00 00 00 00 05 2A 00 00 05 9F
					39 01 00 00 00 00 05 2B 00 00 0C 8F
					/* Loading effect compensation Control */
					39 00 00 00 00 00 03 F0 5A 5A
					39 00 00 00 00 00 04 B0 02 B6 1D
					15 00 00 00 00 00 02 1D 05
					39 01 00 00 00 00 03 F0 A5 A5
					/* Scaler Setting */
					39 00 00 00 00 00 03 F0 5A 5A
					15 00 00 00 00 00 02 C3 00
					39 01 00 00 00 00 03 F0 A5 A5

					/* Brightness Control */
					39 00 00 00 00 00 03 F0 5A 5A
					39 00 00 00 00 00 04 B0 00 0D 63
					15 00 00 00 00 00 02 63 01						/* Dimming Setting */
					39 00 00 00 00 00 04 B0 00 0C 63
					15 00 00 00 00 00 02 63 20
					39 01 00 00 00 00 03 F0 A5 A5
					15 01 00 00 00 00 02 53 20
					//15 01 00 00 00 00 02 F7 0F
					/* ACL Mode */
					39 00 00 00 00 00 03 F0 5A 5A
					15 00 00 00 00 00 02 55 00
					39 01 00 00 00 00 03 F0 A5 A5
					/* Pre-charge setting */
					39 01 00 00 00 00 03 F0 5A 5A
					39 01 00 00 00 00 04 B0 00 2b F6
					39 01 00 00 00 00 04 F6 60 63 69
					39 01 00 00 00 00 02 F7 0F
					39 01 00 00 00 00 03 F0 A5 A5
					/* OPEC ON */
					39 00 00 00 00 00 03 F0 5A 5A
					39 00 00 00 00 00 04 B0 00 56 1F
					39 00 00 00 00 00 11 1F 01 05 01 06 03 24 06 c0 06 c1 0d af 0d b0 1b b0
					39 00 00 00 00 00 04 B0 00 6A 1F
					39 00 00 00 00 00 1D 1F 01 05 03 24 04 4c 05 78 06 c0 08 34 09 c4 0b 54 0d af 0e 10 0e d8 0f a0 10 68 11 30
					39 00 00 00 00 00 04 B0 00 52 1F
					39 00 00 00 00 00 02 1F 02
					39 00 00 00 00 00 04 B0 00 54 1F
					39 00 00 00 00 00 02 1F 00
					39 01 00 00 00 00 03 F0 A5 A5

					/* Display On */
					//05 01 00 00 00 00 01 29
				];
				qcom,mdss-dsi-post-on-backlight = [
					/* Display On */
					05 01 00 00 00 00 01 29
				];
				qcom,mdss-dsi-off-command=[
					05 01 00 00 0A 00 02 28 00
					05 01 00 00 78 00 02 10 00
				];
				qcom,mdss-dsi-lp1-command = [
					05 01 00 00 11 00 01 28
					/* AOD Mode ON Setting */
					39 01 00 00 00 00 03 F0 5A 5A
					15 01 00 00 00 00 02 53 24
					//15 01 00 00 00 00 02 49 01
					39 01 00 00 24 00 03 F0 A5 A5
					05 01 00 00 00 00 01 29
				];
				qcom,mdss-dsi-nolp-command = [
					05 01 00 00 11 00 01 28
					/* AOD OFF */
					39 01 00 00 00 00 03 F0 5A 5A
					15 01 00 00 00 00 02 53 28
					//15 01 00 00 00 00 02 49 02
					39 01 00 00 11 00 03 F0 A5 A5
					/* HBM OFF Mode */
					//39 01 00 00 00 00 02 53 20
					/* display on */
					05 01 00 00 00 00 01 29
				];
				qcom,mdss-dsi-aod-hbm-on-command = [
					/* Loading OFF */
					39 00 00 00 00 00 03 f0 5a 5a
					39 00 00 00 00 00 04 b0 02 b6 1d
					39 00 00 00 00 00 02 1d 05
					39 00 00 00 00 00 03 f0 a5 a5
					/* aor 1.6% */
					39 00 00 00 00 00 03 f0 5a 5a
					39 00 00 00 00 00 04 b0 00 01 bd
					39 00 00 00 00 00 02 bd 02
					39 00 00 00 00 00 04 b0 02 b9 65
					39 00 00 00 00 00 07 65 00 ac 00 ac 00 ac
					39 00 00 00 00 00 02 f7 0f
					39 00 00 00 00 00 03 f0 a5 a5
					/* hbm on */
					15 00 00 00 00 00 02 53 e0
					39 01 00 00 09 00 03 51 0F 1F
				];
				qcom,mdss-dsi-aor-restore-command = [
					/* AOR 16% */
					39 00 00 00 00 00 03 f0 5a 5a
					39 00 00 00 00 00 04 b0 00 01 bd
					39 00 00 00 00 00 02 bd 02
					39 00 00 00 00 00 04 b0 02 b9 65
					39 00 00 00 00 00 07 65 01 5e 01 5e 01 5e
					39 00 00 00 00 00 02 f7 0f
					39 01 00 00 00 00 03 f0 a5 a5
				];
				qcom,mdss-dsi-aod-hbm-off-command = [
					/* HBM OFF Mode */
					//39 01 00 00 00 00 02 53 20
					//39 01 00 00 00 00 03 51 07 FF
					/* AOD ON */
					39 01 00 00 00 00 03 F0 5A 5A
					15 01 00 00 00 00 02 53 24
					39 01 00 00 00 00 02 49 01
					39 01 00 00 09 00 03 F0 A5 A5
				];
				/*** pvt commond for ID1 >= 05 ***/
				qcom,mdss-dsi-lp1-pvt-command = [
					05 01 00 00 11 00 01 28
					/* AOD Mode ON Setting */
					39 01 00 00 00 00 03 F0 5A 5A
					15 01 00 00 00 00 02 53 24
					39 01 00 00 24 00 03 F0 A5 A5
					05 01 00 00 00 00 01 29
				];
				qcom,mdss-dsi-nolp-pvt-command = [
					05 01 00 00 11 00 01 28
					/* AOD OFF */
					39 01 00 00 00 00 03 F0 5A 5A
					15 01 00 00 00 00 02 53 28
					39 01 00 00 11 00 03 F0 A5 A5
					/* HBM OFF Mode */
					//39 01 00 00 11 00 02 53 20
					05 01 00 00 00 00 01 29
				];
				qcom,mdss-dsi-aod-hbm-on-pvt-command = [
					/* Loading OFF */
					39 00 00 00 00 00 03 f0 5a 5a
					39 00 00 00 00 00 04 b0 02 b6 1d
					39 00 00 00 00 00 02 1d 05
					39 00 00 00 00 00 03 f0 a5 a5
					/* aor 1.6% */
					39 00 00 00 00 00 03 f0 5a 5a
					39 00 00 00 00 00 04 b0 00 01 bd
					39 00 00 00 00 00 02 bd 02
					39 00 00 00 00 00 04 b0 02 b9 65
					39 00 00 00 00 00 07 65 00 ac 00 ac 00 ac
					39 00 00 00 00 00 02 f7 0f
					39 00 00 00 00 00 03 f0 a5 a5
					/* hbm on */
					15 00 00 00 00 00 02 53 e0
					39 01 00 00 09 00 03 51 0F 1F
				];
				qcom,mdss-dsi-aod-hbm-off-pvt-command = [
					/* AOD ON */
					39 01 00 00 00 00 03 F0 5A 5A
					15 01 00 00 00 00 02 53 24
					39 01 00 00 09 00 03 F0 A5 A5
				];
				qcom,mdss-dsi-hbm-off-command = [
					/* HBM OFF Mode */
					39 00 00 00 00 00 03 f0 5a 5a
					39 00 00 00 00 00 04 b0 00 0c 63
					15 00 00 00 00 00 02 63 20
					39 00 00 00 00 00 03 f0 a5 a5
					39 01 00 00 09 00 02 53 28
				];
				qcom,mdss-dsi-hbm-on-command = [
					/* DLY ON */
					39 00 00 00 00 00 03 f0 5a 5a
					39 00 00 00 00 00 04 b0 00 0c 63
					39 00 00 00 00 00 02 63 20
					39 01 00 00 09 00 03 f0 a5 a5
					/* Loading OFF */
					39 00 00 00 00 00 03 f0 5a 5a
					39 00 00 00 00 00 04 b0 02 b6 1d
					39 00 00 00 00 00 02 1d 05
					39 00 00 00 00 00 03 f0 a5 a5
					/* aor 1.6% */
					39 00 00 00 00 00 03 f0 5a 5a
					39 00 00 00 00 00 04 b0 00 01 bd
					39 00 00 00 00 00 02 bd 02
					39 00 00 00 00 00 04 b0 02 b9 65
					39 00 00 00 00 00 07 65 00 ac 00 ac 00 ac
					39 00 00 00 00 00 02 f7 0f
					39 00 00 00 00 00 03 f0 a5 a5
					/* hbm on */
					15 01 00 00 09 00 02 53 e0
					39 01 00 00 00 00 03 51 0F 1F
				];
				qcom,mdss-dsi-normal-hbm-on-command = [
					/* Loading OFF */
					39 00 00 00 00 00 03 f0 5a 5a
					39 00 00 00 00 00 04 b0 02 b6 1d
					39 00 00 00 00 00 02 1d 05
					39 00 00 00 00 00 03 f0 a5 a5
					/* aor 1.6% */
					39 00 00 00 00 00 03 f0 5a 5a
					39 00 00 00 00 00 04 b0 00 01 bd
					39 00 00 00 00 00 02 bd 02
					39 00 00 00 00 00 04 b0 02 b9 65
					39 00 00 00 00 00 07 65 00 ac 00 ac 00 ac
					39 00 00 00 00 00 02 f7 0f
					39 00 00 00 00 00 03 f0 a5 a5
					/* hbm on */
					15 01 00 00 09 00 02 53 e0
					39 01 00 00 00 00 03 51 0F 1F
				];
				qcom,mdss-dsi-hbm-enter-switch-command = [
					15 01 00 00 00 00 02 53 E0
				];
				qcom,mdss-dsi-hbm-exit-switch-command = [
					39 01 00 00 00 00 02 53 20
					//39 01 00 00 00 00 03 51 07 FF
				];
				qcom,mdss-dsi-aod-high-mode-command = [
					/* AOD 50nit */
					39 01 00 00 00 00 03 F0 5A 5A
					15 01 00 00 00 00 02 53 24
					39 01 00 00 00 00 03 F0 A5 A5
				];
				qcom,mdss-dsi-aod-low-mode-command = [
					/* AOD 10nit */
					39 01 00 00 00 00 03 F0 5A 5A
					15 01 00 00 00 00 02 53 27
					39 01 00 00 00 00 03 F0 A5 A5
				];
				qcom,mdss-dsi-seed-off-command = [
					/* SEED CRC OFF*/
					15 01 00 00 00 00 02 1C 00
					/* SEED CRC BYPASS */
					39 01 00 00 00 00 03 F0 5A 5A
					15 01 00 00 00 00 02 1D 01
					39 01 00 00 00 00 03 F0 A5 A5
				];
				qcom,mdss-dsi-seed-0-command = [
					/* SEED CRC Setting*/
					15 01 00 00 00 00 02 1C 05
					39 01 00 00 00 00 03 F0 5A 5A
					39 01 00 00 00 00 04 B0 00 01 1D
					/* SEED DCI-P3 Setting*/
					39 01 00 00 00 00 16 1D FF 00 00 00 FF 00 00 00 FF 00 FF FF FF 00 FF FF FF 00 FF FF FF
					15 01 00 00 00 00 02 1D 00
					39 01 00 00 00 00 03 F0 A5 A5
				];
				qcom,mdss-dsi-seed-1-command = [
					/* SEED CRC Setting*/
					15 01 00 00 00 00 02 1C 05
					39 01 00 00 00 00 03 F0 5A 5A
					39 01 00 00 00 00 04 B0 00 01 1D
					/* SEED DCI-P3 Setting*/
					39 01 00 00 00 00 16 1D FF 00 00 00 FF 00 00 00 FF 00 FF FF FF 00 FF FF FF 00 FF FF FF
					15 01 00 00 00 00 02 1D 00
					39 01 00 00 00 00 03 F0 A5 A5
				];
				qcom,mdss-dsi-seed-2-command = [
					/* SEED CRC Setting*/
					15 01 00 00 00 00 02 1C 05
					39 01 00 00 00 00 03 F0 5A 5A
					39 01 00 00 00 00 04 B0 00 01 1D
					/* SEED DCI-P3 Setting*/
					39 01 00 00 00 00 16 1D FF 00 00 00 FF 00 00 00 FF 00 FF FF FF 00 FF FF FF 00 FF FF FF
					15 01 00 00 00 00 02 1D 00
					39 01 00 00 00 00 03 F0 A5 A5
				];
				qcom,mdss-dsi-loading-effect-1-command = [
					39 00 00 00 00 00 03 F0 5A 5A
					39 00 00 00 00 00 04 B0 02 B6 1D
					39 00 00 00 00 00 02 1D 25
					39 00 00 00 00 00 04 B0 01 A5 1F
					39 00 00 00 00 00 09 1F E2 00 00 00 92 2C 6A 80
					39 00 00 00 00 00 04 B0 01 AD 1F
					39 00 00 00 00 00 07 1F 00 00 00 00 FF 90
					39 00 00 00 00 00 04 B0 01 B5 1F
					39 00 00 00 00 00 04 1F 49 00 10
					39 00 00 00 00 00 04 B0 01 BA 1F
					39 00 00 00 00 00 06 1F 05 FF 10 00 00
					39 00 00 00 00 00 04 B0 01 C1 1F
					39 00 00 00 00 00 05 1F 00 00 00 00
					39 00 00 00 00 00 04 B0 01 C5 1F
					39 00 00 00 00 00 05 1F 03 FF 21 3C
					39 01 00 00 00 00 03 F0 A5 A5
				];
				qcom,mdss-dsi-loading-effect-2-command = [
					39 00 00 00 00 00 03 F0 5A 5A
					39 00 00 00 00 00 04 B0 02 B6 1D
					39 00 00 00 00 00 02 1D 25
					39 00 00 00 00 00 04 B0 01 A5 1F
					39 00 00 00 00 00 09 1F E2 00 00 00 92 2C 6A 80
					39 00 00 00 00 00 04 B0 01 AD 1F
					39 00 00 00 00 00 07 1F 7D 64 7E 65 FF 90
					39 00 00 00 00 00 04 B0 01 B5 1F
					39 00 00 00 00 00 04 1F 49 00 10
					39 00 00 00 00 00 04 B0 01 BA 1F
					39 00 00 00 00 00 06 1F 05 FF 10 00 00
					39 00 00 00 00 00 04 B0 01 C1 1F
					39 00 00 00 00 00 05 1F 00 00 00 00
					39 00 00 00 00 00 04 B0 01 C5 1F
					39 00 00 00 00 00 05 1F 03 FF 21 3C
					39 01 00 00 00 00 03 F0 A5 A5
				];
				qcom,mdss-dsi-loading-effect-off-command = [
					39 00 00 00 00 00 03 F0 5A 5A
					39 00 00 00 00 00 04 B0 02 B6 1D
					39 00 00 00 00 00 02 1D 05
					39 01 00 00 00 00 03 F0 A5 A5
				];
				qcom,mdss-dsi-aod-hbm-on-command-state = "dsi_hs_mode";
				qcom,mdss-dsi-aod-hbm-off-command-state = "dsi_hs_mode";
				qcom,mdss-dsi-timing-switch-command-state = "dsi_hs_mode";
				qcom,mdss-dsi-on-command-state = "dsi_lp_mode";
				qcom,mdss-dsi-off-command-state = "dsi_hs_mode";
				qcom,mdss-dsi-seed-off-command-state = "dsi_hs_mode";
				qcom,mdss-dsi-seed-0-command-state = "dsi_hs_mode";
				qcom,mdss-dsi-seed-1-command-state = "dsi_hs_mode";
				qcom,mdss-dsi-seed-2-command-state = "dsi_hs_mode";
				qcom,mdss-dsi-loading-effect-1-command-state = "dsi_hs_mode";
				qcom,mdss-dsi-loading-effect-2-command-state = "dsi_hs_mode";
				qcom,mdss-dsi-loading-effect-off-command-state = "dsi_hs_mode";
				qcom,mdss-dsi-hbm-on-command-state = "dsi_hs_mode";
				qcom,mdss-dsi-hbm-off-command-state = "dsi_hs_mode";
				qcom,mdss-dsi-aor-restore-command-state = "dsi_hs_mode";

				qcom,compression-mode = "dsc";
				qcom,lm-split = <720 720>;
				qcom,mdss-dsc-encoders = <2>;
				qcom,mdss-dsc-slice-height = <24>;
				qcom,mdss-dsc-slice-width = <720>;
				qcom,mdss-dsc-slice-per-pkt = <2>;
				qcom,mdss-dsc-bit-per-component = <10>;
				qcom,mdss-dsc-bit-per-pixel = <8>;
				qcom,mdss-dsc-block-prediction-enable;
				qcom,mdss-dsi-panel-id1-command-state = "dsi_lp_mode";
				qcom,mdss-dsi-panel-read-register-open-state = "dsi_lp_mode";
				qcom,mdss-dsi-panel-read-register-close-state = "dsi_lp_mode";
			};
			timing@sdc_wqhd_90{
				qcom,mdss-dsi-panel-jitter = <0x4 0x1>;
				qcom,mdss-dsc-scr-version = <0x1>;
				qcom,mdss-dsi-timing-default;
				qcom,mdss-mdp-transfer-time-us = <8500>;
				qcom,mdss-dsi-panel-framerate = <90>;
				qcom,mdss-dsi-panel-clockrate = <1100000000>;
				qcom,mdss-dsi-panel-width = <1440>;
				qcom,mdss-dsi-panel-height = <3216>;

				qcom,mdss-dsi-h-front-porch = <68>;
				qcom,mdss-dsi-h-back-porch = <48>;
				qcom,mdss-dsi-h-pulse-width = <12>;
				qcom,mdss-dsi-h-sync-skew = <0>;
				qcom,mdss-dsi-v-back-porch = <8>;
				qcom,mdss-dsi-v-front-porch = <8>;
				qcom,mdss-dsi-v-pulse-width = <8>;
				qcom,mdss-dsi-h-sync-pulse = <0>;

				qcom,mdss-dsi-h-left-border = <0>;
				qcom,mdss-dsi-h-right-border = <0>;
				qcom,mdss-dsi-v-top-border = <0>;
				qcom,mdss-dsi-v-bottom-border = <0>;

				qcom,dsi-select-clocks = "mux_byte_clk0", "mux_pixel_clk0";

				oplus,fod-on-vblank = <0>;
				oplus,fod-off-vblank = <1>;
				qcom,mdss-dsi-panel-read-register-open-command = [
					39 01 00 00 00 00 03 F0 5A 5A
					];
				qcom,mdss-dsi-panel-id1-command = [
					06 01 00 00 00 00 01 E9
					];
				qcom,mdss-dsi-panel-read-register-close-command = [
					39 01 00 00 00 00 03 F0 A5 A5
					];
				qcom,mdss-dsi-timing-switch-command = [
					/* CASET/PASET Setting */
					39 00 00 00 00 00 05 2A 00 00 05 9F
					39 00 00 00 00 00 05 2B 00 00 0C 8F
					/* Scaler Setting */
					39 00 00 00 00 00 03 F0 5A 5A
					15 00 00 00 00 00 02 C3 00
					39 00 00 00 00 00 03 F0 A5 A5

					/* OPLUS ADFR OFF */
					39 00 00 00 00 00 03 F0 5A 5A
					39 00 00 00 00 00 03 FC 5A 5A
					15 00 00 00 00 00 02 B9 00						/* TP shift fixed */
					39 00 00 00 00 00 04 B0 00 02 60
					15 00 00 00 00 00 02 60 00						/* OPLUS ADFR OFF */
					39 00 00 00 00 00 03 F2 00 01					/* 0x01,0x00:ADFR ON setting 0x00,0x01:ADFR OFF Setting */
					15 00 00 00 00 00 02 F7 0F
					39 00 00 00 00 00 03 FC A5 A5
					39 00 00 00 00 00 03 F0 A5 A5

					/* TSP_HSYNC(SYNC1) Fixed Setting */
					39 00 00 00 00 00 03 F0 5A 5A
					39 00 00 00 00 00 04 B0 00 22 B9
					39 00 00 00 00 00 03 B9 A1 B1						/* TSP_SYNC1 = TSP_VSYNC ,  TSP_SYNC2 = TSP_HSYNC */
					39 00 00 00 00 00 04 B0 00 3A B9
					15 00 00 00 00 00 02 B9 03						/* TSP_VSYNC Fixed TE 02:120 03:90 05:60 */
					39 00 00 00 00 00 04 B0 00 26 B9
					39 00 00 00 00 00 03 B9 00 00
					15 00 00 00 00 00 02 F7 0F
					39 00 00 00 00 00 03 F0 A5 A5
					/* TSP_SYNC3 Fixed Setting */
					39 00 00 00 00 00 03 F0 5A 5A
					39 00 00 00 00 00 04 B0 00 24 B9
					15 00 00 00 00 00 02 B9 21
					39 00 00 00 00 00 04 B0 00 38 B9
					15 00 00 00 00 00 02 B9 03						/* TSP_VSYNC Fixed TE 02:120 03:90 05:60 */
					39 00 00 00 00 00 04 B0 00 2A B9
					39 00 00 00 00 00 03 B9 00 00
					15 00 00 00 00 00 02 F7 0F
					39 00 00 00 00 00 03 F0 A5 A5

					/* 90hz Transition */
					39 00 00 00 00 00 03 F0 5A 5A
					39 00 00 00 00 00 04 B0 00 16 F2
					39 00 00 00 00 00 03 F2 24 70					/* 0x1B,0x50:120hz 0x24,0x70:90hz */
					39 00 00 00 00 00 03 BD 21 03					/* 0x21,0x02:120hz 0x21,0x03:90hz */
					15 00 00 00 00 00 02 60 08						/* 0x00:120hz 0x08:90hz 0x01:60hz */
					39 00 00 00 00 00 04 B0 00 10 BD
					15 00 00 00 00 00 02 BD 10						/* 0x00:1frame 0x10:2frame 0x20:3frame */
					15 00 00 00 00 00 02 F7 0F
					39 01 00 00 00 00 03 F0 A5 A5
				];
				qcom,mdss-dsi-on-command = [
					/* DSC Setting */
					39 01 00 00 00 00 5A 9E 11
					00 00 AB 30 80 0C 90 05 A0
					00 18 02 D0 02 D0 02 00 02
					86 00 20 02 83 00 0A 00 0D
					04 86 03 2E 18 00 10 F0 07
					10 20 00 06 0F 0F 33 0E 1C
					2A 38 46 54 62 69 70 77 79
					7B 7D 7E 02 02 22 00 2A 40
					2A BE 3A FC 3A FA 3A F8 3B
					38 3B 78 3B B6 4B B6 4B F4
					4B F4 6C 34 84 74 00
					15 01 00 00 00 00 02 9D 01

					/* Sleep Out(11h) */
					05 01 00 00 05 00 01 11

					/* TSP_HSYNC(SYNC1) Fixed Setting */
					39 00 00 00 00 00 03 F0 5A 5A
					39 00 00 00 00 00 04 B0 00 22 B9
					39 00 00 00 00 00 03 B9 A1 B1						/* TSP_SYNC1 = TSP_VSYNC ,  TSP_SYNC2 = TSP_HSYNC */
					39 00 00 00 00 00 04 B0 00 3A B9
					15 00 00 00 00 00 02 B9 03						/* TSP_VSYNC Fixed TE 02:120 03:90 05:60 */
					39 00 00 00 00 00 04 B0 00 26 B9
					39 00 00 00 00 00 03 B9 00 00
					15 00 00 00 00 00 02 F7 0F
					39 01 00 00 00 00 03 F0 A5 A5
					/* TSP_SYNC3 Fixed Setting */
					39 00 00 00 00 00 03 F0 5A 5A
					39 00 00 00 00 00 04 B0 00 24 B9
					15 00 00 00 00 00 02 B9 21
					39 00 00 00 00 00 04 B0 00 38 B9
					15 00 00 00 00 00 02 B9 03						/* TSP_VSYNC Fixed TE 02:120 03:90 05:60 */
					39 00 00 00 00 00 04 B0 00 2A B9
					39 00 00 00 00 00 03 B9 00 00
					15 00 00 00 00 00 02 F7 0F
					39 01 00 00 78 00 03 F0 A5 A5
					/* 90hz Transition */
					39 00 00 00 00 00 03 F0 5A 5A
					39 00 00 00 00 00 04 B0 00 16 F2
					39 00 00 00 00 00 03 F2 24 70					/* 0x1B,0x50:120hz 0x24,0x70:90hz */
					39 00 00 00 00 00 03 BD 21 03					/* 0x21,0x02:120hz 0x21,0x03:90hz */
					15 00 00 00 00 00 02 60 08						/* 0x00:120hz 0x08:90hz 0x01:60hz */
					39 00 00 00 00 00 04 B0 00 10 BD
					15 00 00 00 00 00 02 BD 10						/* 0x00:1frame 0x10:2frame 0x20:3frame */
					15 00 00 00 00 00 02 F7 0F
					39 01 00 00 00 00 03 F0 A5 A5
					
					/* Common Setting */
					39 00 00 00 00 00 03 F0 5A 5A
					39 00 00 00 00 00 03 F2 00 01					/* FQ_CON Setting */
					39 01 00 00 00 00 03 F0 A5 A5
					/* TE(Vsync) ON */
					39 00 00 00 00 00 03 F0 5A 5A
					15 00 00 00 00 00 02 35 00
					15 00 00 00 00 00 02 B9 00
					39 01 00 00 00 00 03 F0 A5 A5
					/* CASET/PASET Setting */
					39 00 00 00 00 00 05 2A 00 00 05 9F
					39 01 00 00 00 00 05 2B 00 00 0C 8F
					/* Loading effect compensation Control */
					39 00 00 00 00 00 03 F0 5A 5A
					39 00 00 00 00 00 04 B0 02 B6 1D
					15 00 00 00 00 00 02 1D 05
					39 01 00 00 00 00 03 F0 A5 A5
					/* Scaler Setting */
					39 00 00 00 00 00 03 F0 5A 5A
					15 00 00 00 00 00 02 C3 00
					39 01 00 00 00 00 03 F0 A5 A5

					/* Brightness Control */
					39 00 00 00 00 00 03 F0 5A 5A
					39 00 00 00 00 00 04 B0 00 0D 63
					15 00 00 00 00 00 02 63 01						/* Dimming Setting */
					39 00 00 00 00 00 04 B0 00 0C 63
					15 00 00 00 00 00 02 63 20
					39 00 00 00 00 00 03 F0 A5 A5
					15 00 00 00 00 00 02 53 20
					//15 01 00 00 00 00 02 F7 0F
					/* Pre-charge setting */
					39 01 00 00 00 00 03 F0 5A 5A
					39 01 00 00 00 00 04 B0 00 2b F6
					39 01 00 00 00 00 04 F6 60 63 69
					39 01 00 00 00 00 02 F7 0F
					39 01 00 00 00 00 03 F0 A5 A5
					/* OPEC ON */
					39 00 00 00 00 00 03 F0 5A 5A
					39 00 00 00 00 00 04 B0 00 56 1F
					39 00 00 00 00 00 11 1F 01 05 01 06 03 24 06 c0 06 c1 0d af 0d b0 1b b0
					39 00 00 00 00 00 04 B0 00 6A 1F
					39 00 00 00 00 00 1D 1F 01 05 03 24 04 4c 05 78 06 c0 08 34 09 c4 0b 54 0d af 0e 10 0e d8 0f a0 10 68 11 30
					39 00 00 00 00 00 04 B0 00 52 1F
					39 00 00 00 00 00 02 1F 02
					39 00 00 00 00 00 04 B0 00 54 1F
					39 00 00 00 00 00 02 1F 00
					39 01 00 00 00 00 03 F0 A5 A5

					/* ACL Mode */
					39 00 00 00 00 00 03 F0 5A 5A
					15 00 00 00 00 00 02 55 00
					39 00 00 00 00 00 03 F0 A5 A5
					/* Display On */
					//05 01 00 00 00 00 01 29
				];
				qcom,mdss-dsi-post-on-backlight = [
					/* Display On */
					05 01 00 00 00 00 01 29
				];
				qcom,mdss-dsi-off-command=[
					05 01 00 00 0A 00 02 28 00
					05 01 00 00 78 00 02 10 00
				];
				qcom,mdss-dsi-lp1-command = [
					05 01 00 00 11 00 01 28
					/* AOD Mode ON Setting */
					39 01 00 00 00 00 03 F0 5A 5A
					15 01 00 00 00 00 02 53 24
					//15 01 00 00 00 00 02 49 01
					39 01 00 00 24 00 03 F0 A5 A5
					05 01 00 00 00 00 01 29
				];
				qcom,mdss-dsi-nolp-command = [
					/* AOD OFF */
					39 01 00 00 00 00 03 F0 5A 5A
					15 01 00 00 00 00 02 53 28
					//15 01 00 00 00 00 02 49 02
					39 01 00 00 00 00 03 F0 A5 A5

					/* HBM OFF Mode */
					39 01 00 00 00 00 02 53 20
					//39 01 00 00 00 00 03 51 07 FF
				];
				qcom,mdss-dsi-aod-hbm-on-command = [
					/* Loading OFF */
					39 00 00 00 00 00 03 F0 5A 5A
					39 00 00 00 00 00 04 B0 02 B6 1D
					39 00 00 00 00 00 02 1D 05
					39 01 00 00 00 00 03 F0 A5 A5
					/* AOD OFF */
					39 00 00 00 00 00 03 F0 5A 5A
					39 00 00 00 00 00 02 53 20
					15 00 00 00 00 00 02 F7 0F
					15 00 00 00 00 00 02 49 02
					39 01 00 00 00 00 03 F0 A5 A5
					/* AOR 1.6% */
					39 00 00 00 00 00 03 F0 5A 5A
					39 00 00 00 00 00 04 B0 00 01 BD
					39 00 00 00 00 00 02 BD 00
					39 00 00 00 00 00 04 B0 02 D9 65
					39 00 00 00 00 00 07 65 00 AC 00 AC 00 AC
					39 00 00 00 00 00 02 F7 0F
					39 01 00 00 00 00 03 F0 A5 A5
					/* Hbm ON */
					15 01 00 00 00 00 02 53 E0
					39 01 00 00 00 00 03 51 0F 1F
				];
				qcom,mdss-dsi-aod-hbm-off-command = [
					/* HBM OFF Mode */
					39 01 00 00 00 00 02 53 20
					//39 01 00 00 00 00 03 51 07 FF
					/* AOD ON */
					39 01 00 00 00 00 03 F0 5A 5A
					15 01 00 00 00 00 02 53 24
					39 01 00 00 00 00 02 49 01
					39 01 00 00 00 00 03 F0 A5 A5
				];
				/*** pvt commond for ID1 >= 05 ***/
				qcom,mdss-dsi-lp1-pvt-command = [
					05 01 00 00 11 00 01 28
					/* AOD Mode ON Setting */
					39 01 00 00 00 00 03 F0 5A 5A
					15 01 00 00 00 00 02 53 24
					39 01 00 00 24 00 03 F0 A5 A5
					05 01 00 00 00 00 01 29
				];
				qcom,mdss-dsi-nolp-pvt-command = [
					/* AOD OFF */
					39 01 00 00 00 00 03 F0 5A 5A
					15 01 00 00 00 00 02 53 28
					39 01 00 00 00 00 03 F0 A5 A5
					/* HBM OFF Mode */
					39 01 00 00 00 00 02 53 20
					//39 01 00 00 00 00 03 51 07 FF
				];
				qcom,mdss-dsi-aod-hbm-on-pvt-command = [
					/* Loading OFF */
					39 00 00 00 00 00 03 F0 5A 5A
					39 00 00 00 00 00 04 B0 02 B6 1D
					39 00 00 00 00 00 02 1D 05
					39 01 00 00 00 00 03 F0 A5 A5
					/* AOD OFF */
					39 00 00 00 00 00 03 F0 5A 5A
					39 00 00 00 00 00 02 53 28
					39 01 00 00 00 00 03 F0 A5 A5
					/* AOR 1.6% */
					39 00 00 00 00 00 03 F0 5A 5A
					39 00 00 00 00 00 04 B0 00 01 BD
					39 00 00 00 00 00 02 BD 00
					39 00 00 00 00 00 04 B0 02 D9 65
					39 00 00 00 00 00 07 65 00 AC 00 AC 00 AC
					39 00 00 00 00 00 02 F7 0F
					39 01 00 00 00 00 03 F0 A5 A5
					/* Hbm ON */
					15 01 00 00 00 00 02 53 E0
					39 01 00 00 00 00 03 51 0F 1F
				];
				qcom,mdss-dsi-aod-hbm-off-pvt-command = [
					/* HBM OFF Mode */
					39 01 00 00 00 00 02 53 20
					//39 01 00 00 00 00 03 51 07 FF
					/* AOD ON */
					39 01 00 00 00 00 03 F0 5A 5A
					15 01 00 00 00 00 02 53 24
					39 01 00 00 00 00 03 F0 A5 A5
				];
				qcom,mdss-dsi-hbm-off-command = [
					/* HBM OFF Mode */
					39 01 00 00 00 00 02 53 28
					//39 01 00 00 00 00 03 51 07 FF
				];
				qcom,mdss-dsi-hbm-on-command = [
					/* DLY ON */
					39 00 00 00 00 00 03 f0 5a 5a
					39 00 00 00 00 00 04 b0 00 0c 63
					39 00 00 00 00 00 02 63 20
					39 01 00 00 09 00 03 f0 a5 a5
					/* Loading OFF */
					39 00 00 00 00 00 03 F0 5A 5A
					39 00 00 00 00 00 04 B0 02 B6 1D
					39 00 00 00 00 00 02 1D 05
					39 01 00 00 00 00 03 F0 A5 A5
					/* AOR 1.6% */
					39 00 00 00 00 00 03 F0 5A 5A
					39 00 00 00 00 00 04 B0 00 01 BD
					39 00 00 00 00 00 02 BD 00
					39 00 00 00 00 00 04 B0 02 D9 65
					39 00 00 00 00 00 07 65 00 AC 00 AC 00 AC
					39 00 00 00 00 00 02 F7 0F
					39 01 00 00 09 00 03 F0 A5 A5
					/* Hbm ON */
					15 01 00 00 00 00 02 53 E0
					39 01 00 00 09 00 03 51 0F 1F
				];
				qcom,mdss-dsi-normal-hbm-on-command = [
					/* Loading OFF */
					39 00 00 00 00 00 03 F0 5A 5A
					39 00 00 00 00 00 04 B0 02 B6 1D
					39 00 00 00 00 00 02 1D 05
					39 01 00 00 00 00 03 F0 A5 A5
					/* AOR 1.6% */
					39 00 00 00 00 00 03 F0 5A 5A
					39 00 00 00 00 00 04 B0 00 01 BD
					39 00 00 00 00 00 02 BD 00
					39 00 00 00 00 00 04 B0 02 D9 65
					39 00 00 00 00 00 07 65 00 AC 00 AC 00 AC
					39 01 00 00 00 00 02 F7 0F
					39 01 00 00 00 00 03 F0 A5 A5
					/* Hbm ON */
					15 01 00 00 00 00 02 53 E0
					39 01 00 00 00 00 03 51 0F 1F
				];
				qcom,mdss-dsi-hbm-enter-switch-command = [
					15 01 00 00 00 00 02 53 E0
				];
				qcom,mdss-dsi-hbm-exit-switch-command = [
					39 01 00 00 00 00 02 53 20
					//39 01 00 00 00 00 03 51 07 FF
				];
				qcom,mdss-dsi-aor-restore-command = [
					/* AOR 16% */
					39 00 00 00 00 00 03 f0 5a 5a
					39 00 00 00 00 00 04 b0 00 01 bd
					39 00 00 00 00 00 02 bd 03
					39 00 00 00 00 00 04 b0 02 D9 65
					39 00 00 00 00 00 07 65 01 06 01 06 01 06
					39 00 00 00 00 00 02 f7 0f
					39 01 00 00 00 00 03 f0 a5 a5
				];
				qcom,mdss-dsi-aod-high-mode-command = [
					/* AOD 50nit */
					39 01 00 00 00 00 03 F0 5A 5A
					15 01 00 00 00 00 02 53 24
					//39 01 00 00 00 00 02 6A 00
					39 01 00 00 00 00 03 F0 A5 A5
				];
				qcom,mdss-dsi-aod-low-mode-command = [
					/* AOD 10nit */
					39 01 00 00 00 00 03 F0 5A 5A
					15 01 00 00 00 00 02 53 27
					//39 01 00 00 00 00 02 6A 00
					39 01 00 00 00 00 03 F0 A5 A5
				];
				qcom,mdss-dsi-seed-off-command = [
					/* SEED CRC OFF*/
					15 01 00 00 00 00 02 1C 00
					/* SEED CRC BYPASS */
					39 01 00 00 00 00 03 F0 5A 5A
					15 01 00 00 00 00 02 1D 01
					39 01 00 00 00 00 03 F0 A5 A5
				];
				qcom,mdss-dsi-seed-0-command = [
					/* SEED CRC Setting*/
					15 01 00 00 00 00 02 1C 05
					39 01 00 00 00 00 03 F0 5A 5A
					39 01 00 00 00 00 04 B0 00 01 1D
					/* SEED DCI-P3 Setting*/
					39 01 00 00 00 00 16 1D FF 00 00 00 FF 00 00 00 FF 00 FF FF FF 00 FF FF FF 00 FF FF FF
					15 01 00 00 00 00 02 1D 00
					39 01 00 00 00 00 03 F0 A5 A5
				];
				qcom,mdss-dsi-seed-1-command = [
					/* SEED CRC Setting*/
					15 01 00 00 00 00 02 1C 05
					39 01 00 00 00 00 03 F0 5A 5A
					39 01 00 00 00 00 04 B0 00 01 1D
					/* SEED DCI-P3 Setting*/
					39 01 00 00 00 00 16 1D FF 00 00 00 FF 00 00 00 FF 00 FF FF FF 00 FF FF FF 00 FF FF FF
					15 01 00 00 00 00 02 1D 00
					39 01 00 00 00 00 03 F0 A5 A5
				];
				qcom,mdss-dsi-seed-2-command = [
					/* SEED CRC Setting*/
					15 01 00 00 00 00 02 1C 05
					39 01 00 00 00 00 03 F0 5A 5A
					39 01 00 00 00 00 04 B0 00 01 1D
					/* SEED DCI-P3 Setting*/
					39 01 00 00 00 00 16 1D FF 00 00 00 FF 00 00 00 FF 00 FF FF FF 00 FF FF FF 00 FF FF FF
					15 01 00 00 00 00 02 1D 00
					39 01 00 00 00 00 03 F0 A5 A5
				];
				qcom,mdss-dsi-loading-effect-1-command = [
					39 00 00 00 00 00 03 F0 5A 5A
					39 00 00 00 00 00 04 B0 02 B6 1D
					39 00 00 00 00 00 02 1D 25
					39 00 00 00 00 00 04 B0 01 A5 1F
					39 00 00 00 00 00 09 1F E2 00 00 00 92 2C 6A 80
					39 00 00 00 00 00 04 B0 01 AD 1F
					39 00 00 00 00 00 07 1F 00 00 00 00 FF 90
					39 00 00 00 00 00 04 B0 01 B5 1F
					39 00 00 00 00 00 04 1F 49 00 10
					39 00 00 00 00 00 04 B0 01 BA 1F
					39 00 00 00 00 00 06 1F 05 FF 10 00 00
					39 00 00 00 00 00 04 B0 01 C1 1F
					39 00 00 00 00 00 05 1F 00 00 00 00
					39 00 00 00 00 00 04 B0 01 C5 1F
					39 00 00 00 00 00 05 1F 03 FF 21 3C
					39 01 00 00 00 00 03 F0 A5 A5
				];
				qcom,mdss-dsi-loading-effect-2-command = [
					39 00 00 00 00 00 03 F0 5A 5A
					39 00 00 00 00 00 04 B0 02 B6 1D
					39 00 00 00 00 00 02 1D 25
					39 00 00 00 00 00 04 B0 01 A5 1F
					39 00 00 00 00 00 09 1F E2 00 00 00 92 2C 6A 80
					39 00 00 00 00 00 04 B0 01 AD 1F
					39 00 00 00 00 00 07 1F 7D 64 7E 65 FF 90
					39 00 00 00 00 00 04 B0 01 B5 1F
					39 00 00 00 00 00 04 1F 49 00 10
					39 00 00 00 00 00 04 B0 01 BA 1F
					39 00 00 00 00 00 06 1F 05 FF 10 00 00
					39 00 00 00 00 00 04 B0 01 C1 1F
					39 00 00 00 00 00 05 1F 00 00 00 00
					39 00 00 00 00 00 04 B0 01 C5 1F
					39 00 00 00 00 00 05 1F 03 FF 21 3C
					39 01 00 00 00 00 03 F0 A5 A5
				];
				qcom,mdss-dsi-loading-effect-off-command = [
					39 00 00 00 00 00 03 F0 5A 5A
					39 00 00 00 00 00 04 B0 02 B6 1D
					39 00 00 00 00 00 02 1D 05
					39 01 00 00 00 00 03 F0 A5 A5
				];
				qcom,mdss-dsi-aod-hbm-on-command-state = "dsi_hs_mode";
				qcom,mdss-dsi-aod-hbm-off-command-state = "dsi_hs_mode";
				qcom,mdss-dsi-timing-switch-command-state = "dsi_hs_mode";
				qcom,mdss-dsi-on-command-state = "dsi_lp_mode";
				qcom,mdss-dsi-off-command-state = "dsi_hs_mode";
				qcom,mdss-dsi-seed-off-command-state = "dsi_hs_mode";
				qcom,mdss-dsi-seed-0-command-state = "dsi_hs_mode";
				qcom,mdss-dsi-seed-1-command-state = "dsi_hs_mode";
				qcom,mdss-dsi-seed-2-command-state = "dsi_hs_mode";
				qcom,mdss-dsi-loading-effect-1-command-state = "dsi_hs_mode";
				qcom,mdss-dsi-loading-effect-2-command-state = "dsi_hs_mode";
				qcom,mdss-dsi-loading-effect-off-command-state = "dsi_hs_mode";
				qcom,mdss-dsi-hbm-on-command-state = "dsi_hs_mode";
				qcom,mdss-dsi-hbm-off-command-state = "dsi_hs_mode";
				qcom,mdss-dsi-aor-restore-command-state = "dsi_hs_mode";

				qcom,compression-mode = "dsc";
				qcom,lm-split = <720 720>;
				qcom,mdss-dsc-encoders = <2>;
				qcom,mdss-dsc-slice-height = <24>;
				qcom,mdss-dsc-slice-width = <720>;
				qcom,mdss-dsc-slice-per-pkt = <2>;
				qcom,mdss-dsc-bit-per-component = <10>;
				qcom,mdss-dsc-bit-per-pixel = <8>;
				qcom,mdss-dsc-block-prediction-enable;
				qcom,mdss-dsi-panel-id1-command-state = "dsi_lp_mode";
				qcom,mdss-dsi-panel-read-register-open-state = "dsi_lp_mode";
				qcom,mdss-dsi-panel-read-register-close-state = "dsi_lp_mode";
			};
			timing@sdc_wqhd_60{
				qcom,mdss-mdp-transfer-time-us = <7700>;
				qcom,mdss-dsi-panel-jitter = <0x4 0x1>;
				qcom,mdss-dsc-scr-version = <0x1>;
				qcom,mdss-dsi-timing-default;
				qcom,mdss-dsi-panel-framerate = <60>;
				qcom,mdss-dsi-panel-clockrate = <1372000000>;
				qcom,mdss-dsi-panel-width = <1440>;
				qcom,mdss-dsi-panel-height = <3216>;

				qcom,mdss-dsi-h-front-porch = <88>;
				qcom,mdss-dsi-h-back-porch = <48>;
				qcom,mdss-dsi-h-pulse-width = <4>;
				qcom,mdss-dsi-h-sync-skew = <0>;
				qcom,mdss-dsi-v-back-porch = <8>;
				qcom,mdss-dsi-v-front-porch = <8>;
				qcom,mdss-dsi-v-pulse-width = <8>;
				qcom,mdss-dsi-h-sync-pulse = <0>;

				qcom,mdss-dsi-h-left-border = <0>;
				qcom,mdss-dsi-h-right-border = <0>;
				qcom,mdss-dsi-v-top-border = <0>;
				qcom,mdss-dsi-v-bottom-border = <0>;

				qcom,dsi-select-clocks = "mux_byte_clk0", "mux_pixel_clk0";

				oplus,fod-on-vblank = <0>;
				oplus,fod-off-vblank = <0>;
				qcom,mdss-dsi-panel-read-register-open-command = [
					39 01 00 00 00 00 03 F0 5A 5A
					];
				qcom,mdss-dsi-panel-id1-command = [
					06 01 00 00 00 00 01 E9
					];
				qcom,mdss-dsi-panel-read-register-close-command = [
					39 01 00 00 00 00 03 F0 A5 A5
					];
				qcom,mdss-dsi-timing-switch-command = [
					/* CASET/PASET Setting */
					39 00 00 00 00 00 05 2A 00 00 05 9F
					39 00 00 00 00 00 05 2B 00 00 0C 8F
					/* Scaler Setting */
					39 00 00 00 00 00 03 F0 5A 5A
					15 00 00 00 00 00 02 C3 00
					39 00 00 00 00 00 03 F0 A5 A5

					/* OPLUS ADFR OFF */
					39 00 00 00 00 00 03 F0 5A 5A
					39 00 00 00 00 00 03 FC 5A 5A
					15 00 00 00 00 00 02 B9 00						/* TP shift fixed */
					39 00 00 00 00 00 04 B0 00 02 60
					15 00 00 00 00 00 02 60 00						/* OPLUS ADFR OFF */
					39 00 00 00 00 00 03 F2 00 01					/* 0x01,0x00:ADFR ON setting 0x00,0x01:ADFR OFF Setting */
					15 00 00 00 00 00 02 F7 0F
					39 00 00 00 00 00 03 FC A5 A5
					39 00 00 00 00 00 03 F0 A5 A5

					/* TSP_HSYNC(SYNC1) Fixed Setting */
					39 00 00 00 00 00 03 F0 5A 5A
					39 00 00 00 00 00 04 B0 00 22 B9
					39 00 00 00 00 00 03 B9 A1 B1						/* TSP_SYNC1 = TSP_VSYNC ,  TSP_SYNC2 = TSP_HSYNC */
					39 00 00 00 00 00 04 B0 00 3A B9
					15 00 00 00 00 00 02 B9 05						/* TSP_VSYNC Fixed TE 02:120 03:90 05:60 */
					39 00 00 00 00 00 04 B0 00 26 B9
					39 00 00 00 00 00 03 B9 00 00
					15 00 00 00 00 00 02 F7 0F
					39 00 00 00 00 00 03 F0 A5 A5
					/* TSP_SYNC3 Fixed Setting */
					39 00 00 00 00 00 03 F0 5A 5A
					39 00 00 00 00 00 04 B0 00 24 B9
					15 00 00 00 00 00 02 B9 21
					39 00 00 00 00 00 04 B0 00 38 B9
					15 00 00 00 00 00 02 B9 05						/* TSP_VSYNC Fixed TE 02:120 03:90 05:60 */
					39 00 00 00 00 00 04 B0 00 2A B9
					39 00 00 00 00 00 03 B9 00 00
					15 00 00 00 00 00 02 F7 0F
					39 00 00 00 00 00 03 F0 A5 A5

					/* 60hz Transition */
					39 00 00 00 00 00 03 F0 5A 5A
					39 00 00 00 00 00 04 B0 00 16 F2
					39 00 00 00 00 00 03 F2 1B 50					/* 0x1B,0x50:120hz 0x24,0x70:90hz */
					39 00 00 00 00 00 03 BD 21 02					/* 0x21,0x02:120hz 0x21,0x03:90hz */
					15 00 00 00 00 00 02 60 01						/* 0x00:120hz 0x08:90hz 0x01:60hz */
					39 00 00 00 00 00 04 B0 00 10 BD
					15 00 00 00 00 00 02 BD 00						/* HOP force off */
					15 00 00 00 00 00 02 F7 0F
					39 01 00 00 00 00 03 F0 A5 A5
				];
				qcom,mdss-dsi-on-command = [
					/* DSC Setting */
					39 01 00 00 00 00 5A 9E 11
					00 00 AB 30 80 0C 90 05 A0
					00 18 02 D0 02 D0 02 00 02
					86 00 20 02 83 00 0A 00 0D
					04 86 03 2E 18 00 10 F0 07
					10 20 00 06 0F 0F 33 0E 1C
					2A 38 46 54 62 69 70 77 79
					7B 7D 7E 02 02 22 00 2A 40
					2A BE 3A FC 3A FA 3A F8 3B
					38 3B 78 3B B6 4B B6 4B F4
					4B F4 6C 34 84 74 00
					15 01 00 00 00 00 02 9D 01

					/* Sleep Out(11h) */
					05 01 00 00 05 00 01 11

					/* TSP_HSYNC(SYNC1) Fixed Setting */
					39 00 00 00 00 00 03 F0 5A 5A
					39 00 00 00 00 00 04 B0 00 22 B9
					39 00 00 00 00 00 03 B9 A1 B1						/* TSP_SYNC1 = TSP_VSYNC ,  TSP_SYNC2 = TSP_HSYNC */
					39 00 00 00 00 00 04 B0 00 3A B9
					15 00 00 00 00 00 02 B9 05						/* TSP_VSYNC Fixed TE 02:120 03:90 05:60 */
					39 00 00 00 00 00 04 B0 00 26 B9
					39 00 00 00 00 00 03 B9 00 00
					15 00 00 00 00 00 02 F7 0F
					39 01 00 00 00 00 03 F0 A5 A5
					/* TSP_SYNC3 Fixed Setting */
					39 00 00 00 00 00 03 F0 5A 5A
					39 00 00 00 00 00 04 B0 00 24 B9
					15 00 00 00 00 00 02 B9 21
					39 00 00 00 00 00 04 B0 00 38 B9
					15 00 00 00 00 00 02 B9 05						/* TSP_VSYNC Fixed TE 02:120 03:90 05:60 */
					39 00 00 00 00 00 04 B0 00 2A B9
					39 00 00 00 00 00 03 B9 00 00
					15 00 00 00 00 00 02 F7 0F
					39 01 00 00 78 00 03 F0 A5 A5
					/* 60hz Transition */
					39 00 00 00 00 00 03 F0 5A 5A
					39 00 00 00 00 00 04 B0 00 16 F2
					39 00 00 00 00 00 03 F2 1B 50					/* 0x1B,0x50:120hz 0x24,0x70:90hz */
					39 00 00 00 00 00 03 BD 21 02					/* 0x21,0x02:120hz 0x21,0x03:90hz */
					15 00 00 00 00 00 02 60 01						/* 0x00:120hz 0x08:90hz 0x01:60hz */
					39 00 00 00 00 00 04 B0 00 10 BD
					15 00 00 00 00 00 02 BD 00						/* HOP force off */
					15 00 00 00 00 00 02 F7 0F
					39 01 00 00 00 00 03 F0 A5 A5

					/* Common Setting */
					39 00 00 00 00 00 03 F0 5A 5A
					39 00 00 00 00 00 03 F2 00 01					/* FQ_CON Setting */
					39 01 00 00 00 00 03 F0 A5 A5
					/* TE(Vsync) ON */
					39 00 00 00 00 00 03 F0 5A 5A
					15 00 00 00 00 00 02 35 00
					15 00 00 00 00 00 02 B9 00
					39 01 00 00 00 00 03 F0 A5 A5
					/* CASET/PASET Setting */
					39 00 00 00 00 00 05 2A 00 00 05 9F
					39 01 00 00 00 00 05 2B 00 00 0C 8F
					/* Loading effect compensation Control */
					39 00 00 00 00 00 03 F0 5A 5A
					39 00 00 00 00 00 04 B0 02 B6 1D
					15 00 00 00 00 00 02 1D 05
					39 01 00 00 00 00 03 F0 A5 A5
					/* Scaler Setting */
					39 00 00 00 00 00 03 F0 5A 5A
					15 00 00 00 00 00 02 C3 00
					39 01 00 00 00 00 03 F0 A5 A5

					/* Brightness Control */
					39 00 00 00 00 00 03 F0 5A 5A
					39 00 00 00 00 00 04 B0 00 0D 63
					15 00 00 00 00 00 02 63 01						/* Dimming Setting */
					39 00 00 00 00 00 04 B0 00 0C 63
					15 00 00 00 00 00 02 63 20
					39 01 00 00 00 00 03 F0 A5 A5
					15 01 00 00 00 00 02 53 20
					//15 01 00 00 00 00 02 F7 0F
					/* Pre-charge setting */
					39 01 00 00 00 00 03 F0 5A 5A
					39 01 00 00 00 00 04 B0 00 2b F6
					39 01 00 00 00 00 04 F6 60 63 69
					39 01 00 00 00 00 02 F7 0F
					39 01 00 00 00 00 03 F0 A5 A5
					/* OPEC ON */
					39 00 00 00 00 00 03 F0 5A 5A
					39 00 00 00 00 00 04 B0 00 56 1F
					39 00 00 00 00 00 11 1F 01 05 01 06 03 24 06 c0 06 c1 0d af 0d b0 1b b0
					39 00 00 00 00 00 04 B0 00 6A 1F
					39 00 00 00 00 00 1D 1F 01 05 03 24 04 4c 05 78 06 c0 08 34 09 c4 0b 54 0d af 0e 10 0e d8 0f a0 10 68 11 30
					39 00 00 00 00 00 04 B0 00 52 1F
					39 00 00 00 00 00 02 1F 02
					39 00 00 00 00 00 04 B0 00 54 1F
					39 00 00 00 00 00 02 1F 00
					39 01 00 00 00 00 03 F0 A5 A5

					/* ACL Mode */
					39 00 00 00 00 00 03 F0 5A 5A
					15 00 00 00 00 00 02 55 00
					39 01 00 00 00 00 03 F0 A5 A5

					/* Display On */
					//05 01 00 00 00 00 01 29
				];
				qcom,mdss-dsi-post-on-backlight = [
					/* Display On */
					05 01 00 00 00 00 01 29
				];
				qcom,mdss-dsi-off-command=[
					05 01 00 00 0A 00 02 28 00
					05 01 00 00 78 00 02 10 00
				];
				qcom,mdss-dsi-lp1-command = [
					05 01 00 00 11 00 01 28
					/* AOD Mode ON Setting */
					39 01 00 00 00 00 03 F0 5A 5A
					15 01 00 00 00 00 02 53 24
					//15 01 00 00 00 00 02 49 01
					39 01 00 00 24 00 03 F0 A5 A5
					05 01 00 00 00 00 01 29
				];
				qcom,mdss-dsi-nolp-command = [
					/* AOD OFF */
					39 01 00 00 00 00 03 F0 5A 5A
					15 01 00 00 00 00 02 53 28
					//15 01 00 00 00 00 02 49 02
					39 01 00 00 00 00 03 F0 A5 A5
					/* ELVSS DIM OFF  */
					39 01 00 00 00 00 03 F0 5A 5A
					39 01 00 00 00 00 04 B0 00 0C 63
					15 01 00 00 00 00 02 63 00
					39 01 00 00 00 00 03 F0 A5 A5
					/* HBM OFF Mode */
					39 01 00 00 00 00 02 53 20
					//39 01 00 00 00 00 03 51 07 FF
				];
				qcom,mdss-dsi-aod-hbm-on-command = [
					/* Loading OFF */
					39 00 00 00 00 00 03 F0 5A 5A
					39 00 00 00 00 00 04 B0 02 B6 1D
					39 00 00 00 00 00 02 1D 05
					39 00 00 00 00 00 03 F0 A5 A5
					/* AOD OFF */
					39 00 00 00 00 00 03 F0 5A 5A
					39 00 00 00 00 00 02 53 28
					39 01 00 00 00 00 03 F0 A5 A5
					/* Hbm ON */
					15 01 00 00 00 00 02 53 E0
					39 01 00 00 00 00 03 51 0F 1F
				];
				qcom,mdss-dsi-aod-hbm-off-command = [
					/* HBM OFF Mode */
					39 01 00 00 00 00 02 53 20
					//39 01 00 00 00 00 03 51 07 FF
					/* AOD 50nit */
					39 01 00 00 00 00 03 F0 5A 5A
					15 01 00 00 00 00 02 53 24
					//39 01 00 00 00 00 02 6A 00
					15 01 00 00 00 00 02 F7 0F
					//15 01 00 00 00 00 02 49 01
					39 01 00 00 00 00 03 F0 A5 A5
				];
				/*** pvt commond for ID1 >= 05 ***/
				qcom,mdss-dsi-lp1-pvt-command = [
					05 01 00 00 11 00 01 28
					/* AOD Mode ON Setting */
					39 01 00 00 00 00 03 F0 5A 5A
					15 01 00 00 00 00 02 53 24
					39 01 00 00 24 00 03 F0 A5 A5
					05 01 00 00 00 00 01 29
				];
				qcom,mdss-dsi-nolp-pvt-command = [
					/* AOD OFF */
					39 01 00 00 00 00 03 F0 5A 5A
					15 01 00 00 00 00 02 53 28
					39 01 00 00 00 00 03 F0 A5 A5
					/* HBM OFF Mode */
					39 01 00 00 00 00 02 53 20
				];
				qcom,mdss-dsi-aod-hbm-on-pvt-command = [
					/* Loading OFF */
					39 00 00 00 00 00 03 F0 5A 5A
					39 00 00 00 00 00 04 B0 02 B6 1D
					39 00 00 00 00 00 02 1D 05
					39 01 00 00 00 00 03 F0 A5 A5
					/* AOD OFF */
					39 00 00 00 00 00 03 F0 5A 5A
					39 00 00 00 00 00 02 53 28
					39 01 00 00 00 00 03 F0 A5 A5
					/* AOR 1.6% */
					39 00 00 00 00 00 03 F0 5A 5A
					39 00 00 00 00 00 04 B0 00 01 BD
					39 00 00 00 00 00 02 BD 02
					39 00 00 00 00 00 04 B0 02 b9 65
					39 00 00 00 00 00 07 65 00 AC 00 AC 00 AC
					39 00 00 00 00 00 02 F7 0F
					39 01 00 00 00 00 03 F0 A5 A5
					/* Hbm ON */
					15 01 00 00 00 00 02 53 E0
					39 01 00 00 00 00 03 51 0F 1F
				];
				qcom,mdss-dsi-aod-hbm-off-pvt-command = [
					/* HBM OFF Mode */
					39 01 00 00 00 00 02 53 20
					/* AOD ON */
					39 01 00 00 00 00 03 F0 5A 5A
					15 01 00 00 00 00 02 53 24
					39 01 00 00 00 00 03 F0 A5 A5
				];
				qcom,mdss-dsi-hbm-off-command = [
					/* HBM OFF Mode */
					39 00 00 00 00 00 03 f0 5a 5a
					39 00 00 00 00 00 04 b0 00 0c 63
					15 00 00 00 00 00 02 63 20
					39 00 00 00 00 00 03 f0 a5 a5
					39 01 00 00 00 00 02 53 28
				];
				qcom,mdss-dsi-hbm-on-command = [
					/* elvss dim off + dly on */
					39 00 00 00 00 00 03 f0 5a 5a
					39 00 00 00 00 00 04 b0 00 0c 63
					15 00 00 00 00 00 02 63 20
					39 00 00 00 00 00 03 f0 a5 a5
					/* Loading OFF */
					39 00 00 00 00 00 03 f0 5a 5a
					39 00 00 00 00 00 04 b0 02 b6 1d
					39 00 00 00 00 00 02 1d 05
					39 00 00 00 00 00 03 f0 a5 a5
					/* aor 1.6% */
					39 00 00 00 00 00 03 f0 5a 5a
					39 00 00 00 00 00 04 b0 00 01 bd
					39 00 00 00 00 00 02 bd 02
					39 00 00 00 00 00 04 b0 02 b9 65
					39 00 00 00 00 00 07 65 00 ac 00 ac 00 ac
					39 00 00 00 00 00 02 f7 0f
					39 00 00 00 00 00 03 f0 a5 a5
					15 01 00 00 09 00 02 53 e0
					39 01 00 00 00 00 03 51 0F 1F
				];
				qcom,mdss-dsi-normal-hbm-on-command = [
					/* elvss dim off + dly on */
					39 00 00 00 00 00 03 f0 5a 5a
					39 00 00 00 00 00 04 b0 00 0c 63
					15 00 00 00 00 00 02 63 20
					39 00 00 00 00 00 03 f0 a5 a5
					/* Loading OFF */
					39 00 00 00 00 00 03 f0 5a 5a
					39 00 00 00 00 00 04 b0 02 b6 1d
					39 00 00 00 00 00 02 1d 05
					39 00 00 00 00 00 03 f0 a5 a5
					/* aor 1.6% */
					39 00 00 00 00 00 03 f0 5a 5a
					39 00 00 00 00 00 04 b0 00 01 bd
					39 00 00 00 00 00 02 bd 02
					39 00 00 00 00 00 04 b0 02 b9 65
					39 00 00 00 00 00 07 65 00 ac 00 ac 00 ac
					39 00 00 00 00 00 02 f7 0f
					39 00 00 00 00 00 03 f0 a5 a5
					15 01 00 00 09 00 02 53 e0
					39 01 00 00 00 00 03 51 0F 1F
				];
				qcom,mdss-dsi-hbm-enter-switch-command = [
					15 01 00 00 00 00 02 53 E0
				];
				qcom,mdss-dsi-hbm-exit-switch-command = [
					39 01 00 00 00 00 02 53 20
					//39 01 00 00 00 00 03 51 07 FF
				];
				qcom,mdss-dsi-aor-restore-command = [
					/* AOR 16% */
					39 00 00 00 00 00 03 f0 5a 5a
					39 00 00 00 00 00 04 b0 00 01 bd
					39 00 00 00 00 00 02 bd 02
					39 00 00 00 00 00 04 b0 02 b9 65
					39 00 00 00 00 00 07 65 01 5e 01 5e 01 5e
					39 00 00 00 00 00 02 f7 0f
					39 01 00 00 00 00 03 f0 a5 a5
				];
				qcom,mdss-dsi-aod-high-mode-command = [
					/* AOD 50nit */
					39 01 00 00 00 00 03 F0 5A 5A
					15 01 00 00 00 00 02 53 24
					//39 01 00 00 00 00 02 6A 00
					39 01 00 00 00 00 03 F0 A5 A5
				];
				qcom,mdss-dsi-aod-low-mode-command = [
					/* AOD 10nit */
					39 01 00 00 00 00 03 F0 5A 5A
					15 01 00 00 00 00 02 53 27
					//39 01 00 00 00 00 02 6A 00
					39 01 00 00 00 00 03 F0 A5 A5
				];
				qcom,mdss-dsi-seed-off-command = [
					/* SEED CRC OFF*/
					15 01 00 00 00 00 02 1C 00
					/* SEED CRC BYPASS */
					39 01 00 00 00 00 03 F0 5A 5A
					15 01 00 00 00 00 02 1D 01
					39 01 00 00 00 00 03 F0 A5 A5
				];
				qcom,mdss-dsi-seed-0-command = [
					/* SEED CRC Setting*/
					15 01 00 00 00 00 02 1C 05
					39 01 00 00 00 00 03 F0 5A 5A
					39 01 00 00 00 00 04 B0 00 01 1D
					/* SEED DCI-P3 Setting*/
					39 01 00 00 00 00 16 1D FF 00 00 00 FF 00 00 00 FF 00 FF FF FF 00 FF FF FF 00 FF FF FF
					15 01 00 00 00 00 02 1D 00
					39 01 00 00 00 00 03 F0 A5 A5
				];
				qcom,mdss-dsi-seed-1-command = [
					/* SEED CRC Setting*/
					15 01 00 00 00 00 02 1C 05
					39 01 00 00 00 00 03 F0 5A 5A
					39 01 00 00 00 00 04 B0 00 01 1D
					/* SEED DCI-P3 Setting*/
					39 01 00 00 00 00 16 1D FF 00 00 00 FF 00 00 00 FF 00 FF FF FF 00 FF FF FF 00 FF FF FF
					15 01 00 00 00 00 02 1D 00
					39 01 00 00 00 00 03 F0 A5 A5
				];
				qcom,mdss-dsi-seed-2-command = [
					/* SEED CRC Setting*/
					15 01 00 00 00 00 02 1C 05
					39 01 00 00 00 00 03 F0 5A 5A
					39 01 00 00 00 00 04 B0 00 01 1D
					/* SEED DCI-P3 Setting*/
					39 01 00 00 00 00 16 1D FF 00 00 00 FF 00 00 00 FF 00 FF FF FF 00 FF FF FF 00 FF FF FF
					15 01 00 00 00 00 02 1D 00
					39 01 00 00 00 00 03 F0 A5 A5
				];
				qcom,mdss-dsi-loading-effect-1-command = [
					39 00 00 00 00 00 03 F0 5A 5A
					39 00 00 00 00 00 04 B0 02 B6 1D
					39 00 00 00 00 00 02 1D 25
					39 00 00 00 00 00 04 B0 01 A5 1F
					39 00 00 00 00 00 09 1F E2 00 00 00 92 2C 6A 80
					39 00 00 00 00 00 04 B0 01 AD 1F
					39 00 00 00 00 00 07 1F 00 00 00 00 FF 90
					39 00 00 00 00 00 04 B0 01 B5 1F
					39 00 00 00 00 00 04 1F 49 00 10
					39 00 00 00 00 00 04 B0 01 BA 1F
					39 00 00 00 00 00 06 1F 05 FF 10 00 00
					39 00 00 00 00 00 04 B0 01 C1 1F
					39 00 00 00 00 00 05 1F 00 00 00 00
					39 00 00 00 00 00 04 B0 01 C5 1F
					39 00 00 00 00 00 05 1F 03 FF 21 3C
					39 01 00 00 00 00 03 F0 A5 A5
				];
				qcom,mdss-dsi-loading-effect-2-command = [
					39 00 00 00 00 00 03 F0 5A 5A
					39 00 00 00 00 00 04 B0 02 B6 1D
					39 00 00 00 00 00 02 1D 25
					39 00 00 00 00 00 04 B0 01 A5 1F
					39 00 00 00 00 00 09 1F E2 00 00 00 92 2C 6A 80
					39 00 00 00 00 00 04 B0 01 AD 1F
					39 00 00 00 00 00 07 1F 7D 64 7E 65 FF 90
					39 00 00 00 00 00 04 B0 01 B5 1F
					39 00 00 00 00 00 04 1F 49 00 10
					39 00 00 00 00 00 04 B0 01 BA 1F
					39 00 00 00 00 00 06 1F 05 FF 10 00 00
					39 00 00 00 00 00 04 B0 01 C1 1F
					39 00 00 00 00 00 05 1F 00 00 00 00
					39 00 00 00 00 00 04 B0 01 C5 1F
					39 00 00 00 00 00 05 1F 03 FF 21 3C
					39 01 00 00 00 00 03 F0 A5 A5
				];
				qcom,mdss-dsi-loading-effect-off-command = [
					39 00 00 00 00 00 03 F0 5A 5A
					39 00 00 00 00 00 04 B0 02 B6 1D
					39 00 00 00 00 00 02 1D 05
					39 01 00 00 00 00 03 F0 A5 A5
				];
				qcom,mdss-dsi-aod-hbm-on-command-state = "dsi_hs_mode";
				qcom,mdss-dsi-aod-hbm-off-command-state = "dsi_hs_mode";
				qcom,mdss-dsi-timing-switch-command-state = "dsi_hs_mode";
				qcom,mdss-dsi-on-command-state = "dsi_lp_mode";
				qcom,mdss-dsi-off-command-state = "dsi_hs_mode";
				qcom,mdss-dsi-seed-off-command-state = "dsi_hs_mode";
				qcom,mdss-dsi-seed-0-command-state = "dsi_hs_mode";
				qcom,mdss-dsi-seed-1-command-state = "dsi_hs_mode";
				qcom,mdss-dsi-seed-2-command-state = "dsi_hs_mode";
				qcom,mdss-dsi-loading-effect-1-command-state = "dsi_hs_mode";
				qcom,mdss-dsi-loading-effect-2-command-state = "dsi_hs_mode";
				qcom,mdss-dsi-loading-effect-off-command-state = "dsi_hs_mode";
				qcom,mdss-dsi-hbm-on-command-state = "dsi_hs_mode";
				qcom,mdss-dsi-hbm-off-command-state = "dsi_hs_mode";
				qcom,mdss-dsi-qsync-on-commands-state = "dsi_hs_mode";
				qcom,mdss-dsi-qsync-off-commands-state = "dsi_hs_mode";
				qcom,mdss-dsi-aor-restore-command-state = "dsi_hs_mode";

				qcom,compression-mode = "dsc";
				qcom,lm-split = <720 720>;
				qcom,mdss-dsc-encoders = <2>;
				qcom,mdss-dsc-slice-height = <24>;
				qcom,mdss-dsc-slice-width = <720>;
				qcom,mdss-dsc-slice-per-pkt = <2>;
				qcom,mdss-dsc-bit-per-component = <10>;
				qcom,mdss-dsc-bit-per-pixel = <8>;
				qcom,mdss-dsc-block-prediction-enable;
				qcom,mdss-dsi-panel-id1-command-state = "dsi_lp_mode";
				qcom,mdss-dsi-panel-read-register-open-state = "dsi_lp_mode";
				qcom,mdss-dsi-panel-read-register-close-state = "dsi_lp_mode";
			};
		};
	};
};

&dsi_oplus20061_samsung_1440_3216_dsc_cmd_dvt_id09 {
	qcom,panel-supply-entries = <&dsi_panel_pwr_supply>;
	qcom,mdss-dsi-bl-pmic-control-type = "bl_ctrl_dcs";
	qcom,mdss-dsi-dc-backlight-level = <520>;
	qcom,mdss-dsi-bl-min-level = <1>;
	qcom,mdss-dsi-bl-normal-max-level = <2047>;
	qcom,mdss-dsi-bl-max-level = <4095>;
	qcom,mdss-brightness-normal-max-level = <2047>;
	qcom,mdss-brightness-max-level = <4095>;
	qcom,mdss-brightness-default-level = <400>;
	qcom,platform-te-gpio = <&tlmm 66 0>;
	qcom,platform-reset-gpio = <&tlmm 75 0>;
	qcom,platform-panel-vout-gpio = <&tlmm 8 0>;
	qcom,platform-panel-te-esd-gpio = <&tlmm 109 0>;
	qcom,platform-panel-vddr-aod-en-gpio = <&tlmm 139 0>;
	qcom,ulps-enabled;
	qcom,dsi-select-clocks = "mux_byte_clk0", "mux_pixel_clk0";

	oplus,dsi-fod-brightness = <0 0xff>,
			<2 0xf2>,
			<4 0xed>,
			<6 0xec>,
			<8 0xea>,
			<10 0xe9>,
			<20 0xe4>,
			<40 0xdc>,
			<60 0xd4>,
			<90 0xca>,
			<140 0xc0>,
			<200 0xb4>,
			<300 0xa4>,
			<450 0x93>,
			<600 0x81>,
			<750 0x77>,
			<900 0x69>,
			<1050 0x60>,
			<1200 0x54>,
			<1400 0x49>,
			<1600 0x3c>,
			<1800 0x32>,
			<2047 0x24>;

	oplus,dsi-dc-brightness = <0 0xff>,
			<2 0xFC>,
			<4 0xF9>,
			<6 0xF9>,
			<8 0xF8>,
			<10 0xF7>,
			<15 0xF6>,
			<20 0xF4>,
			<30 0xF0>,
			<40 0xEB>,
			<50 0xE6>,
			<60 0xE1>,
			<70 0xDD>,
			<80 0xD8>,
			<100 0xCF>,
			<120 0xC5>,
			<150 0xB9>,
			<200 0xA2>,
			<250 0x8C>,
			<300 0x76>,
			<350 0x5B>,
			<400 0x44>,
			<450 0x2C>,
			<500 0x0D>,
			<520 0x00>;

	qcom,mdss-dsi-display-timings {
		timing@sdc_fhd_120 { /* FHD+ 120hz 412.8Mhz 825.6Mbps */
			qcom,mdss-dsi-panel-phy-timings = [00 1C 07 07 17 22 07 07 08 02 04 00 18 0C];
			qcom,display-topology = <1 1 1>,<2 2 1>;
			qcom,default-topology-index = <1>;
		};
		timing@sdc_fhd_90 { /* FHD+ 90hz 412.8Mhz 825.6Mbps  */
			qcom,mdss-dsi-panel-phy-timings = [00 1C 07 07 17 22 07 07 08 02 04 00 18 0C];
			qcom,display-topology = <1 1 1>,<2 2 1>;
			qcom,default-topology-index = <1>;
		};
		timing@sdc_fhd_60 { /* FHD+ 60hz 412.8Mhz 825.6Mbps */
			qcom,mdss-dsi-panel-phy-timings = [00 1C 07 07 17 22 07 07 08 02 04 00 18 0C];
			qcom,display-topology = <1 1 1>,<2 2 1>;
			qcom,default-topology-index = <1>;
		};
		timing@sdc_wqhd_120 { /* WQHD+ 120hz 686Mhz 1372Mbps */
			qcom,mdss-dsi-panel-phy-timings = [00 2C 0C 0C 1D 27 09 0C 0B 02 04 00 24 11];
			qcom,display-topology = <1 1 1>,<2 2 1>;
			qcom,default-topology-index = <1>;
		};
		timing@sdc_wqhd_90 { /* WQHD+ 90hz 505Mhz 1100Mbps */
			qcom,mdss-dsi-panel-phy-timings = [00 24 0A 0A 1A 25 09 0A 09 02 04 00 1E 0F];
			qcom,display-topology = <1 1 1>,<2 2 1>;
			qcom,default-topology-index = <1>;
		};
		timing@sdc_wqhd_60 { /* WQHD+ 60hz 686Mhz 1372Mbps */
			qcom,mdss-dsi-panel-phy-timings = [00 2C 0C 0C 1D 27 09 0C 0B 02 04 00 24 11];
			qcom,display-topology = <1 1 1>,<2 2 1>;
			qcom,default-topology-index = <1>;
		};
	};
};
&dsi_oplus20061_samsung_1440_3216_dsc_cmd_dvt_id09 {
	qcom,panel_voltage_vddi_name = "vddio";
	qcom,panel_voltage_vddi = <0 1650000 1800000 1950000>;
	qcom,panel_voltage_vddr_name = "vddio";
	qcom,panel_voltage_vddr = <1 1650000 1800000 1950000>;
};

&dsi_oplus20061_samsung_1440_3216_dsc_cmd_dvt_id09 {
	oplus,color_vivid_status;
	oplus,color_srgb_status;
	oplus,apollo_backlight_enable;
};

// #ifdef OPLUS_FEATURE_ADFR
// this file is too large, so add OPlus ADFR timing in a overlay dtsi
#include "dsi-panel-oplus20061-samsung-1440-3216-dsc-cmd-dvt-overlay-id09.dtsi"
// #endif
